VERSION ""

NS_ :

BS_:

BU_: CH DIPF DIPR ETH FC HVI HVS PARTY SDCV VEH VIRT

BO_ 905 DAS_status2: 8 PARTY
 SG_ DAS_status2Checksum : 56|8@1+ (1,0) [0|255] ""  aps
 SG_ DAS_status2Counter : 52|4@1+ (1,0) [0|15] ""  aps
 SG_ DAS_longCollisionWarning : 48|4@1+ (1,0) [0|15] ""  aps
 SG_ DAS_ppOffsetDesiredRamp : 40|8@1+ (0.01,-1.28) [-1.28|1.27] "m"  aps
 SG_ DAS_driverInteractionLevel : 38|2@1+ (1,0) [0|2] ""  aps
 SG_ DAS_robState : 36|2@1+ (1,0) [0|3] ""  aps
 SG_ DAS_radarTelemetry : 34|2@1+ (1,0) [0|2] ""  aps
 SG_ DAS_lssState : 31|3@1+ (1,0) [0|7] ""  aps
 SG_ DAS_ACC_report : 26|5@1+ (1,0) [0|24] ""  aps
 SG_ DAS_pmmCameraFaultReason : 24|2@1+ (1,0) [0|2] ""  aps
 SG_ DAS_pmmSysFaultReason : 21|3@1+ (1,0) [0|7] ""  aps
 SG_ DAS_pmmRadarFaultReason : 19|2@1+ (1,0) [0|2] ""  aps
 SG_ DAS_pmmUltrasonicsFaultReason : 16|3@1+ (1,0) [0|4] ""  aps
 SG_ DAS_activationFailureStatus : 14|2@1+ (1,0) [0|2] ""  aps
 SG_ DAS_pmmLoggingRequest : 13|1@1+ (1,0) [0|1] ""  aps
 SG_ DAS_pmmObstacleSeverity : 10|3@1+ (1,0) [0|7] ""  aps
 SG_ DAS_accSpeedLimit : 0|10@1+ (0.4,0) [0|204.6] "mph"  aps

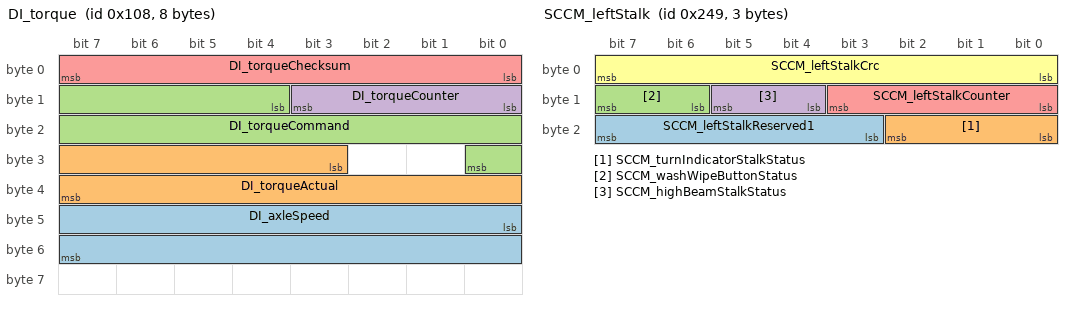
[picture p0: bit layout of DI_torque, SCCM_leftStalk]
BO_ 264 DI_torque: 8 PARTY
 SG_ DI_axleSpeed : 40|16@1- (0.1,0.0) [-2750|2750] "RPM"  epas3s
 SG_ DI_torqueActual : 27|13@1- (2,0) [-7500|7500] "Nm"  X
 SG_ DI_torqueCommand : 12|13@1- (2,0) [-7500|7500] "Nm"  X
 SG_ DI_torqueCounter : 8|4@1+ (1,0) [0|15] ""  epas3s
 SG_ DI_torqueChecksum : 0|8@1+ (1,0) [0|255] ""  epas3s

BO_ 585 SCCM_leftStalk: 3 PARTY
 SG_ SCCM_leftStalkReserved1 : 19|5@1+ (1,0) [0|31] ""  X
 SG_ SCCM_turnIndicatorStalkStatus : 16|3@1+ (1,0) [0|5] ""  park
 SG_ SCCM_washWipeButtonStatus : 14|2@1+ (1,0) [0|3] ""  X
 SG_ SCCM_highBeamStalkStatus : 12|2@1+ (1,0) [0|3] ""  X
 SG_ SCCM_leftStalkCounter : 8|4@1+ (1,0) [0|15] ""  X
 SG_ SCCM_leftStalkCrc : 0|8@1+ (1,0) [0|255] ""  X

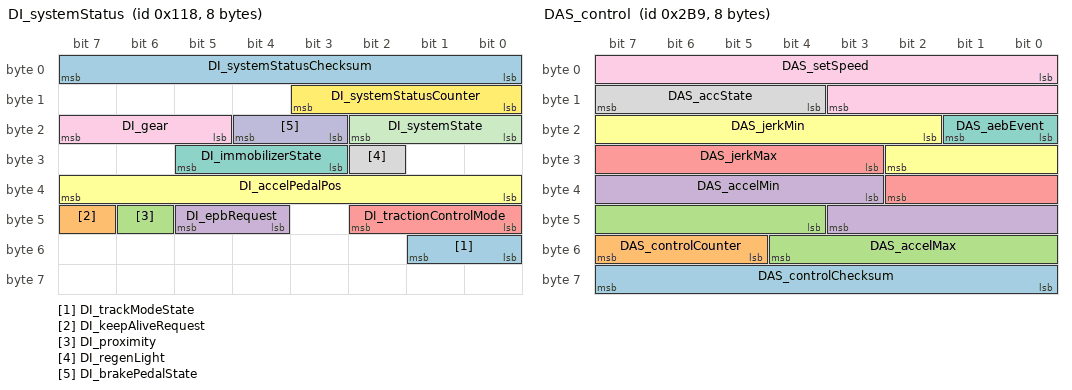
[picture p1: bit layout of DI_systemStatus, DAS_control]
BO_ 280 DI_systemStatus: 8 PARTY
 SG_ DI_trackModeState : 48|2@1+ (1,0) [0|2] ""  X
 SG_ DI_keepAliveRequest : 47|1@1+ (1,0) [0|1] ""  X
 SG_ DI_proximity : 46|1@1+ (1,0) [0|1] ""  X
 SG_ DI_epbRequest : 44|2@1+ (1,0) [0|2] ""  X
 SG_ DI_tractionControlMode : 40|3@1+ (1,0) [0|5] ""  X
 SG_ DI_accelPedalPos : 32|8@1+ (0.4,0) [0|100] "%"  X
 SG_ DI_immobilizerState : 27|3@1+ (1,0) [0|6] ""  X
 SG_ DI_regenLight : 26|1@1+ (1,0) [0|1] ""  X
 SG_ DI_gear : 21|3@1+ (1,0) [0|7] ""  park
 SG_ DI_brakePedalState : 19|2@1+ (1,0) [0|2] ""  X
 SG_ DI_systemState : 16|3@1+ (1,0) [0|5] ""  X
 SG_ DI_systemStatusCounter : 8|4@1+ (1,0) [0|15] ""  X
 SG_ DI_systemStatusChecksum : 0|8@1+ (1,0) [0|255] ""  X

BO_ 697 DAS_control: 8 PARTY
 SG_ DAS_controlChecksum : 56|8@1+ (1,0) [0|255] ""  aps
 SG_ DAS_controlCounter : 53|3@1+ (1,0) [0|7] ""  aps
 SG_ DAS_accelMax : 44|9@1+ (0.04,-15) [-15|5.44] "m/s^2"  aps
 SG_ DAS_accelMin : 35|9@1+ (0.04,-15) [-15|5.44] "m/s^2"  aps
 SG_ DAS_jerkMax : 27|8@1+ (0.034,0) [0|8.67] "m/s^3"  aps
 SG_ DAS_jerkMin : 18|9@1+ (0.018,-9.1) [-9.1|0.097999999999999] "m/s^3"  aps
 SG_ DAS_aebEvent : 16|2@1+ (1,0) [0|3] ""  aps
 SG_ DAS_accState : 12|4@1+ (1,0) [0|15] ""  aps
 SG_ DAS_setSpeed : 0|12@1+ (0.1,0) [0|409.4] "kph"  aps

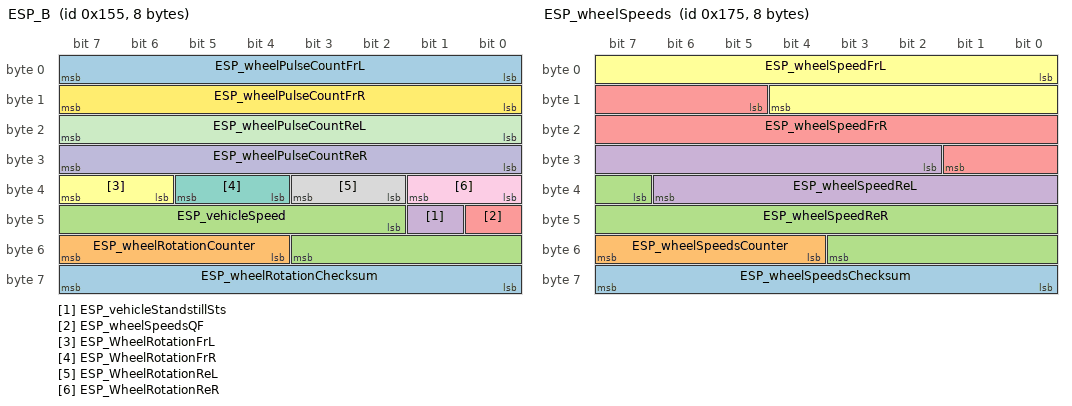
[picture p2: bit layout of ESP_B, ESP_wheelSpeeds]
BO_ 341 ESP_B: 8 PARTY
 SG_ ESP_wheelRotationChecksum : 56|8@1+ (1,0) [0|255] ""  app
 SG_ ESP_wheelRotationCounter : 52|4@1+ (1,0) [0|15] ""  app
 SG_ ESP_vehicleSpeed : 42|10@1+ (0.5,0) [0|511] "kph"  app
 SG_ ESP_vehicleStandstillSts : 41|1@1+ (1,0) [0|1] ""  park
 SG_ ESP_wheelSpeedsQF : 40|1@1+ (1,0) [0|1] ""  epas3s
 SG_ ESP_WheelRotationFrL : 38|2@1+ (1,0) [0|3] ""  aps
 SG_ ESP_WheelRotationFrR : 36|2@1+ (1,0) [0|3] ""  aps
 SG_ ESP_WheelRotationReL : 34|2@1+ (1,0) [0|3] ""  aps
 SG_ ESP_WheelRotationReR : 32|2@1+ (1,0) [0|3] ""  aps
 SG_ ESP_wheelPulseCountReR : 24|8@1+ (1,0) [0|254] "1"  das
 SG_ ESP_wheelPulseCountReL : 16|8@1+ (1,0) [0|254] "1"  das
 SG_ ESP_wheelPulseCountFrR : 8|8@1+ (1,0) [0|254] "1"  app
 SG_ ESP_wheelPulseCountFrL : 0|8@1+ (1,0) [0|254] "1"  app

BO_ 373 ESP_wheelSpeeds: 8 CH
 SG_ ESP_wheelSpeedsChecksum : 56|8@1+ (1,0) [0|255] ""  das
 SG_ ESP_wheelSpeedsCounter : 52|4@1+ (1,0) [0|15] ""  das
 SG_ ESP_wheelSpeedReR : 39|13@1+ (0.04,0) [0|327.64] "km/h"  das
 SG_ ESP_wheelSpeedReL : 26|13@1+ (0.04,0) [0|327.64] "km/h"  das
 SG_ ESP_wheelSpeedFrR : 13|13@1+ (0.04,0) [0|327.64] "km/h"  das
 SG_ ESP_wheelSpeedFrL : 0|13@1+ (0.04,0) [0|327.64] "km/h"  das

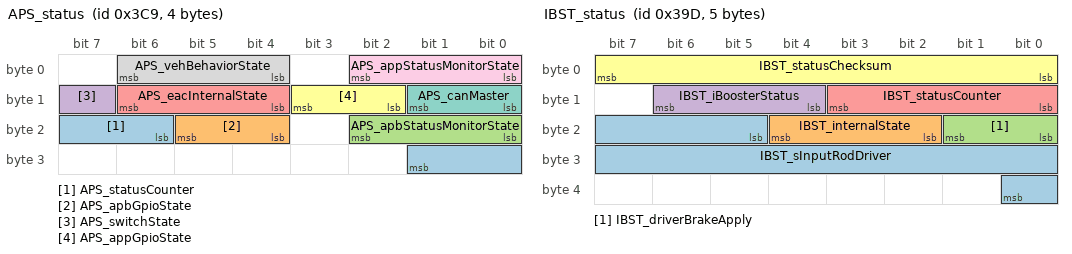
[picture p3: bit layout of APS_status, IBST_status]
BO_ 969 APS_status: 4 PARTY
 SG_ APS_statusCounter : 22|4@1+ (1,0) [0|15] ""  X
 SG_ APS_apbGpioState : 20|2@1+ (1,0) [0|3] ""  gtw
 SG_ APS_apbStatusMonitorState : 16|3@1+ (1,0) [0|7] ""  gtw
 SG_ APS_switchState : 15|1@1+ (1,0) [0|1] ""  X
 SG_ APS_eacInternalState : 12|3@1+ (1,0) [0|7] ""  gtw
 SG_ APS_appGpioState : 10|2@1+ (1,0) [0|3] ""  gtw
 SG_ APS_canMaster : 8|2@1+ (1,0) [0|3] ""  gtw
 SG_ APS_vehBehaviorState : 4|3@1+ (1,0) [0|7] ""  gtw
 SG_ APS_appStatusMonitorState : 0|3@1+ (1,0) [0|7] ""  gtw

BO_ 925 IBST_status: 5 PARTY
 SG_ IBST_sInputRodDriver : 21|12@1+ (0.015625,-5) [-5|47] "mm"  gtw
 SG_ IBST_internalState : 18|3@1+ (1,0) [0|6] ""  gtw
 SG_ IBST_driverBrakeApply : 16|2@1+ (1,0) [0|3] ""  gtw
 SG_ IBST_iBoosterStatus : 12|3@1+ (1,0) [0|6] ""  gtw
 SG_ IBST_statusCounter : 8|4@1+ (1,0) [0|15] ""  X
 SG_ IBST_statusChecksum : 0|8@1+ (1,0) [0|255] ""  X

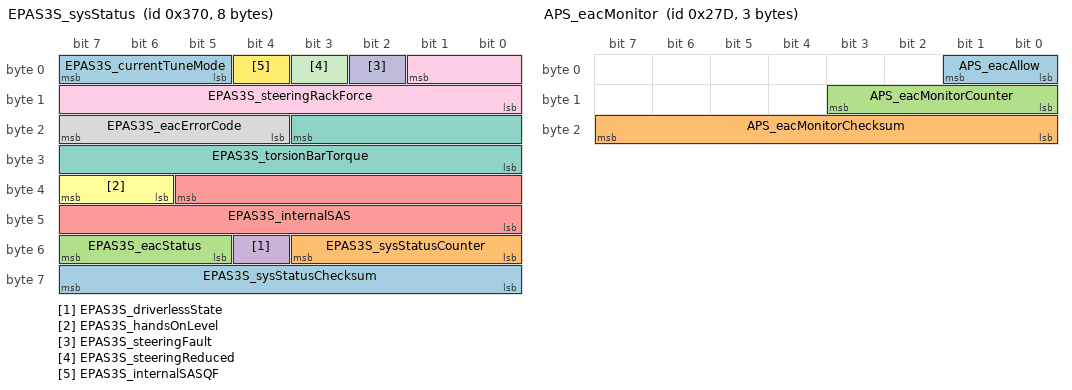
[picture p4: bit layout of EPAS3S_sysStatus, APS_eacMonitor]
BO_ 880 EPAS3S_sysStatus: 8 PARTY
 SG_ EPAS3S_sysStatusChecksum : 56|8@1+ (1,0) [0|255] ""  park
 SG_ EPAS3S_sysStatusCounter : 48|4@1+ (1,0) [0|15] ""  gtw
 SG_ EPAS3S_eacStatus : 55|3@0+ (1,0) [0|7] ""  das
 SG_ EPAS3S_driverlessState : 52|1@0+ (1,0) [0|1] ""  das
 SG_ EPAS3S_internalSAS : 37|14@0+ (0.1,-819.2) [-819.2|819] "deg"  das
 SG_ EPAS3S_handsOnLevel : 39|2@0+ (1,0) [0|3] ""  das
 SG_ EPAS3S_torsionBarTorque : 19|12@0+ (0.01,-20.5) [-20.5|20.45] "Nm"  das
 SG_ EPAS3S_eacErrorCode : 23|4@0+ (1,0) [0|15] ""  das
 SG_ EPAS3S_steeringRackForce : 1|10@0+ (50,-25575) [-25575|25575] "N"  gtw
 SG_ EPAS3S_steeringFault : 2|1@0+ (1,0) [0|1] ""  das
 SG_ EPAS3S_steeringReduced : 3|1@0+ (1,0) [0|1] ""  das
 SG_ EPAS3S_internalSASQF : 4|1@0+ (1,0) [0|1] ""  gtw
 SG_ EPAS3S_currentTuneMode : 7|3@0+ (1,0) [0|5] ""  gtw

BO_ 637 APS_eacMonitor: 3 PARTY
 SG_ APS_eacAllow : 0|2@1+ (1,0) [0|0] "" X
 SG_ APS_eacMonitorChecksum : 16|8@1+ (1,0) [0|0] "" X
 SG_ APS_eacMonitorCounter : 8|4@1+ (1,0) [0|0] "" X

BO_ 545 VCFRONT_LVPowerState: 8 CH
 SG_ VCFRONT_LVPowerStateChecksum : 56|8@1+ (1,0) [0|255] ""  ibst
 SG_ VCFRONT_LVPowerStateCounter : 52|4@1+ (1,0) [0|15] ""  ibst
 SG_ VCFRONT_uiAudioLVState m0 : 50|2@1+ (1,0) [0|3] ""  X
 SG_ VCFRONT_uiHiCurrentLVState m0 : 48|2@1+ (1,0) [0|3] ""  X
 SG_ VCFRONT_vcrightHiCurrentLVState m0 : 46|2@1+ (1,0) [0|3] ""  X
 SG_ VCFRONT_vcleftHiCurrentLVState m0 : 44|2@1+ (1,0) [0|3] ""  X
 SG_ VCFRONT_ocsLVRequest m0 : 42|2@1+ (1,0) [0|3] ""  X
 SG_ VCFRONT_oilPumpRearLVRequest m0 : 40|2@1+ (1,0) [0|3] ""  X
 SG_ VCFRONT_oilPumpFrontLVState m0 : 38|2@1+ (1,0) [0|3] ""  X
 SG_ VCFRONT_disLVState m0 : 36|2@1+ (1,0) [0|3] ""  X
 SG_ VCFRONT_diLVRequest m0 : 34|2@1+ (1,0) [0|3] ""  X
 SG_ VCFRONT_das2HighCurrentLVState m0 : 32|2@1+ (1,0) [0|3] ""  das
 SG_ VCFRONT_das1HighCurrentLVState m0 : 30|2@1+ (1,0) [0|3] ""  das
 SG_ VCFRONT_amplifierLVRequest m0 : 28|2@1+ (1,0) [0|3] ""  X
 SG_ VCFRONT_tunerLVRequest m0 : 26|2@1+ (1,0) [0|3] ""  X
 SG_ VCFRONT_iBoosterLVState m0 : 24|2@1+ (1,0) [0|3] ""  ibst
 SG_ VCFRONT_rcmLVRequest m0 : 22|2@1+ (1,0) [0|3] ""  rcm
 SG_ VCFRONT_tpmsLVRequest m0 : 20|2@1+ (1,0) [0|3] ""  tpms
 SG_ VCFRONT_sccmLVRequest m0 : 18|2@1+ (1,0) [0|3] ""  X
 SG_ VCFRONT_pcsLVState m1 : 16|2@1+ (1,0) [0|3] ""  X
 SG_ VCFRONT_ptcLVRequest m0 : 16|2@1+ (1,0) [0|3] ""  X
 SG_ VCFRONT_hvacCompLVState m0 : 14|2@1+ (1,0) [0|3] ""  X
 SG_ VCFRONT_tasLVState m1 : 14|2@1+ (1,0) [0|3] ""  X
 SG_ VCFRONT_hvcLVRequest m1 : 12|2@1+ (1,0) [0|3] ""  X
 SG_ VCFRONT_radcLVState m0 : 12|2@1+ (1,0) [0|3] ""  X
 SG_ VCFRONT_epasLVState m1 : 10|2@1+ (1,0) [0|3] ""  epas3s
 SG_ VCFRONT_espLVState m0 : 10|2@1+ (1,0) [0|3] ""  ibst
 SG_ VCFRONT_parkLVState m0 : 8|2@1+ (1,0) [0|3] ""  X
 SG_ VCFRONT_cpLVRequest m1 : 8|2@1+ (1,0) [0|3] ""  X
 SG_ VCFRONT_vehiclePowerState : 5|2@1+ (1,0) [0|3] ""  park
 SG_ VCFRONT_LVPowerStateIndex M : 0|5@1+ (1,0) [0|1] ""  epas3s

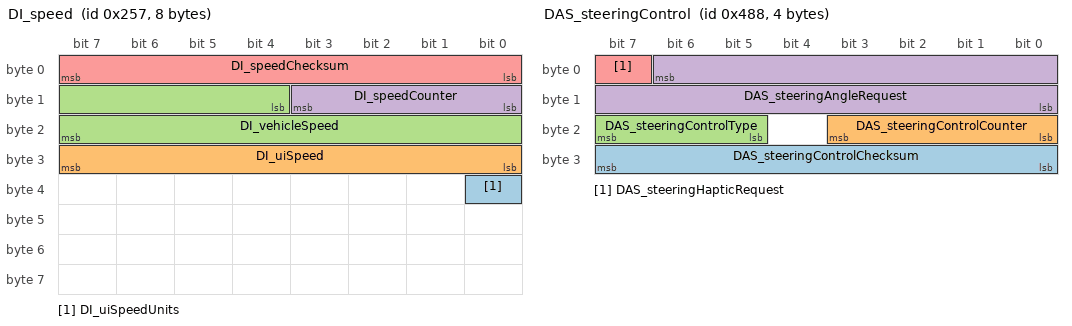
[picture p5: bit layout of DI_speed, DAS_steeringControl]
BO_ 599 DI_speed: 8 PARTY
 SG_ DI_uiSpeedUnits : 32|1@1+ (1,0) [0|1] ""  das
 SG_ DI_uiSpeed : 24|8@1+ (1,0) [0|254] ""  das
 SG_ DI_vehicleSpeed : 12|12@1+ (0.08,-40) [-40|285] "kph"  park
 SG_ DI_speedCounter : 8|4@1+ (1,0) [0|15] ""  park
 SG_ DI_speedChecksum : 0|8@1+ (1,0) [0|255] ""  park

BO_ 605 DAS_road: 6 XXX
 SG_ DAS_stopLineDist : 16|8@1+ (0.5,0) [0|127.5] "m" XXX
 SG_ DAS_trafficLightColor : 26|3@0+ (1,0) [0|7] "" XXX

BO_ 1160 DAS_steeringControl: 4 PARTY
 SG_ DAS_steeringControlChecksum : 24|8@1+ (1,0) [0|255] ""  aps
 SG_ DAS_steeringControlCounter : 16|4@1+ (1,0) [0|15] ""  aps
 SG_ DAS_steeringControlType : 23|3@0+ (1,0) [0|7] ""  aps
 SG_ DAS_steeringAngleRequest : 6|15@0+ (0.1,-1638.35) [-1638.35|1638.35] "deg"  aps
 SG_ DAS_steeringHapticRequest : 7|1@0+ (1,0) [0|1] ""  aps

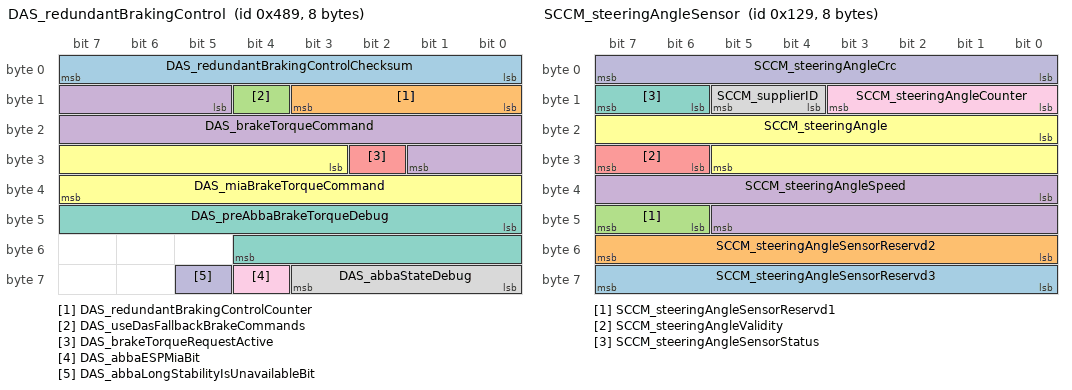
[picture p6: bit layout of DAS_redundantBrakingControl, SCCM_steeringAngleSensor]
BO_ 1161 DAS_redundantBrakingControl: 8 XXX
 SG_ DAS_redundantBrakingControlChecksum : 0|8@1+ (1,0) [0|255] "" XXX
 SG_ DAS_redundantBrakingControlCounter : 8|4@1+ (1,0) [0|15] "" XXX
 SG_ DAS_useDasFallbackBrakeCommands : 12|1@1+ (1,0) [0|1] "" XXX
 SG_ DAS_brakeTorqueCommand : 13|13@1+ (3,0) [0|24573] "" XXX
 SG_ DAS_brakeTorqueRequestActive : 26|1@1+ (1,0) [0|1] "" XXX
 SG_ DAS_miaBrakeTorqueCommand : 27|13@1+ (3,0) [0|24573] "" XXX
 SG_ DAS_preAbbaBrakeTorqueDebug : 40|13@1+ (3,0) [0|24573] "" XXX
 SG_ DAS_abbaStateDebug : 56|4@1+ (1,0) [0|15] "" XXX
 SG_ DAS_abbaESPMiaBit : 60|1@1+ (1,0) [0|1] "" XXX
 SG_ DAS_abbaLongStabilityIsUnavailableBit : 61|1@1+ (1,0) [0|1] "" XXX

BO_ 297 SCCM_steeringAngleSensor: 8 PARTY
 SG_ SCCM_steeringAngleSensorReservd3 : 56|8@1+ (1,0) [0|255] ""  X
 SG_ SCCM_steeringAngleSensorReservd2 : 48|8@1+ (1,0) [0|255] ""  X
 SG_ SCCM_steeringAngleSensorReservd1 : 46|2@1+ (1,0) [0|3] ""  X
 SG_ SCCM_steeringAngleSpeed : 32|14@1+ (0.5,-4096) [-4096|4095.5] "deg/s"  park
 SG_ SCCM_steeringAngleValidity : 30|2@1+ (1,0) [0|3] ""  park
 SG_ SCCM_steeringAngle : 16|14@1+ (0.1,-819.2) [-819.2|819] "deg"  epas3s
 SG_ SCCM_steeringAngleSensorStatus : 14|2@1+ (1,0) [0|3] ""  epas3s
 SG_ SCCM_supplierID : 12|2@1+ (1,0) [0|3] ""  park
 SG_ SCCM_steeringAngleCounter : 8|4@1+ (1,0) [0|15] ""  epas3s
 SG_ SCCM_steeringAngleCrc : 0|8@1+ (1,0) [0|255] ""  epas3s

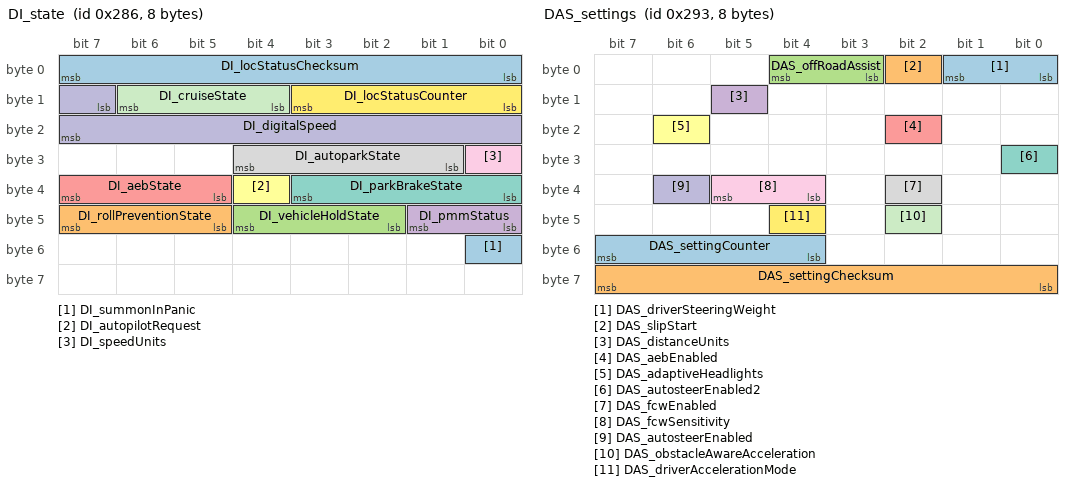
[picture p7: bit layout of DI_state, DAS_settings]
BO_ 646 DI_state: 8 ETH
 SG_ DI_summonInPanic : 48|1@1+ (1,0) [0|0] ""  X
 SG_ DI_rollPreventionState : 45|3@1+ (1,0) [0|0] ""  X
 SG_ DI_vehicleHoldState : 42|3@1+ (1,0) [0|0] ""  X
 SG_ DI_pmmStatus : 40|2@1+ (1,0) [0|0] ""  X
 SG_ DI_aebState : 37|3@1+ (1,0) [0|0] ""  X
 SG_ DI_autopilotRequest : 36|1@1+ (1,0) [0|0] ""  X
 SG_ DI_parkBrakeState : 32|4@1+ (1,0) [0|0] ""  X
 SG_ DI_autoparkState : 25|4@1+ (1,0) [0|0] ""  X
 SG_ DI_speedUnits : 24|1@1+ (1,0) [0|0] ""  X
 SG_ DI_digitalSpeed : 15|9@1+ (0.5,0) [0|0] "speed"  X
 SG_ DI_cruiseState : 12|3@1+ (1,0) [0|0] ""  X
 SG_ DI_locStatusCounter : 8|4@1+ (1,0) [0|0] ""  X
 SG_ DI_locStatusChecksum : 0|8@1+ (1,0) [0|0] ""  X

BO_ 659 DAS_settings: 8 XXX
 SG_ DAS_driverSteeringWeight : 1|2@0+ (1,0) [0|255] "" XXX
 SG_ DAS_slipStart : 2|1@0+ (1,0) [0|1] "" XXX
 SG_ DAS_offRoadAssist : 3|2@1+ (1,0) [0|63] "" XXX
 SG_ DAS_distanceUnits : 13|1@1+ (1,0) [0|255] "" XXX
 SG_ DAS_aebEnabled : 18|1@0+ (1,0) [0|255] "" XXX
 SG_ DAS_adaptiveHeadlights : 22|1@1+ (1,0) [0|31] "" XXX
 SG_ DAS_autosteerEnabled2 : 24|1@0+ (1,0) [0|1] "" XXX
 SG_ DAS_fcwEnabled : 34|1@0+ (1,0) [0|1] "" XXX
 SG_ DAS_fcwSensitivity : 37|2@0+ (1,0) [0|63] "" XXX
 SG_ DAS_autosteerEnabled : 38|1@0+ (1,0) [0|1] "" XXX
 SG_ DAS_obstacleAwareAcceleration : 42|1@0+ (1,0) [0|1] "" XXX
 SG_ DAS_driverAccelerationMode : 44|1@1+ (1,0) [0|127] "" XXX
 SG_ DAS_settingCounter : 52|4@1+ (1,0) [0|15] "" XXX
 SG_ DAS_settingChecksum : 56|8@1+ (1,0) [0|255] "" XXX

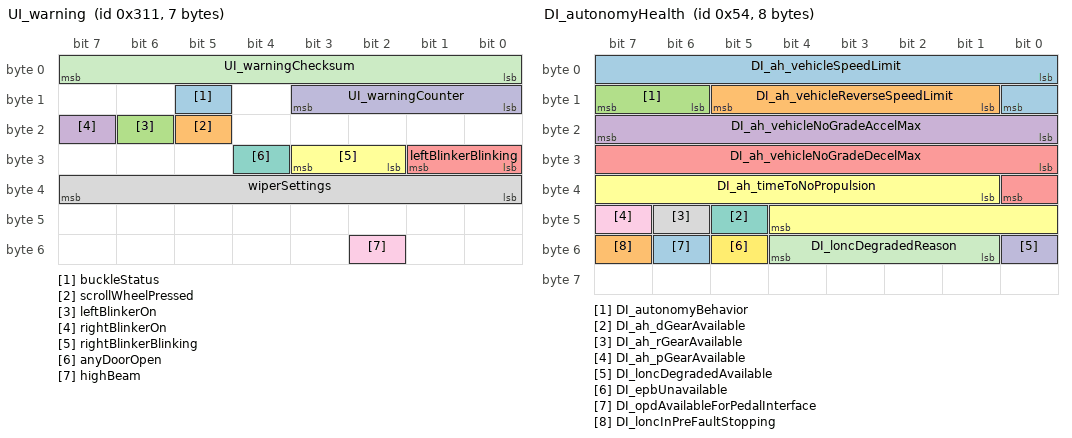
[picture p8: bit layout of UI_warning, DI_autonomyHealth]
BO_ 785 UI_warning: 7 XXX
 SG_ buckleStatus : 13|1@0+ (1,0) [0|1] "" XXX
 SG_ scrollWheelPressed : 21|1@0+ (1,0) [0|1] "" XXX
 SG_ leftBlinkerOn : 22|1@0+ (1,0) [0|1] "" XXX
 SG_ rightBlinkerOn : 23|1@0+ (1,0) [0|1] "" XXX
 SG_ leftBlinkerBlinking : 25|2@0+ (1,0) [0|3] "" XXX
 SG_ rightBlinkerBlinking : 26|2@1+ (1,0) [0|15] "" XXX
 SG_ anyDoorOpen : 28|1@0+ (1,0) [0|1] "" XXX
 SG_ wiperSettings : 39|8@0+ (1,0) [0|255] "" XXX
 SG_ highBeam : 50|1@0+ (1,0) [0|1] "" XXX
 SG_ UI_warningCounter : 8|4@1+ (1,0) [0|15] "" XXX
 SG_ UI_warningChecksum : 0|8@1+ (1,0) [0|255] "" XXX

BO_ 923 DAS_status: 8 PARTY
 SG_ DAS_statusChecksum : 56|8@1+ (1,0) [0|255] ""  aps
 SG_ DAS_statusCounter : 52|4@1+ (1,0) [0|15] ""  aps
 SG_ DAS_summonAvailable : 51|1@1+ (1,0) [0|1] ""  aps
 SG_ DAS_autoLaneChangeState : 46|5@1+ (1,0) [0|31] ""  aps
 SG_ DAS_autopilotHandsOnState : 42|4@1+ (1,0) [0|15] ""  aps
 SG_ DAS_fleetSpeedState : 40|2@1+ (1,0) [0|3] ""  aps
 SG_ DAS_laneDepartureWarning : 37|3@1+ (1,0) [0|5] ""  aps
 SG_ DAS_csaState : 35|2@1+ (1,0) [0|3] ""  aps
 SG_ DAS_sideCollisionInhibit : 34|1@1+ (1,0) [0|1] ""  aps
 SG_ DAS_sideCollisionWarning : 32|2@1+ (1,0) [0|3] ""  aps
 SG_ DAS_sideCollisionAvoid : 30|2@1+ (1,0) [0|3] ""  aps
 SG_ DAS_summonRvsLeashReached : 29|1@1+ (1,0) [0|1] ""  aps
 SG_ DAS_summonFwdLeashReached : 28|1@1+ (1,0) [0|1] ""  aps
 SG_ DAS_autoparkWaitingForBrake : 26|1@1+ (1,0) [0|1] ""  gtw
 SG_ DAS_autoParked : 25|1@1+ (1,0) [0|1] ""  aps
 SG_ DAS_autoparkReady : 24|1@1+ (1,0) [0|1] ""  aps
 SG_ DAS_forwardCollisionWarning : 22|2@1+ (1,0) [0|3] ""  aps
 SG_ DAS_heaterState : 21|1@1+ (1,0) [0|1] ""  gtw
 SG_ DAS_visionOnlySpeedLimit : 16|5@1+ (5,0) [0|150] "kph/mph"  aps
 SG_ DAS_summonClearedGate : 15|1@1+ (1,0) [0|1] ""  aps
 SG_ DAS_summonObstacle : 14|1@1+ (1,0) [0|1] ""  aps
 SG_ DAS_suppressSpeedWarning : 13|1@1+ (1,0) [0|1] ""  aps
 SG_ DAS_fusedSpeedLimit : 8|5@1+ (5,0) [0|150] "kph/mph"  aps
 SG_ DAS_blindSpotRearRight : 6|2@1+ (1,0) [0|3] ""  aps
 SG_ DAS_blindSpotRearLeft : 4|2@1+ (1,0) [0|3] ""  aps
 SG_ DAS_autopilotState : 0|4@1+ (1,0) [0|15] ""  aps

BO_ 325 ESP_status: 8 PARTY
 SG_ ESP_absBrakeEvent2 : 22|2@1+ (1,0) [0|0] ""  X
 SG_ ESP_absFaultLamp : 17|1@1+ (1,0) [0|0] ""  X
 SG_ ESP_brakeApply : 31|1@1+ (1,0) [0|0] ""  X
 SG_ ESP_brakeDiscWipingActive : 28|1@1+ (1,0) [0|0] ""  X
 SG_ ESP_brakeLamp : 21|1@1+ (1,0) [0|0] ""  X
 SG_ ESP_brakeTorqueTarget : 51|13@1+ (2,0) [0|0] "Nm"  X
 SG_ ESP_btcTargetState : 38|2@1+ (1,0) [0|0] ""  X
 SG_ ESP_cdpStatus : 34|2@1+ (1,0) [0|0] ""  X
 SG_ ESP_driverBrakeApply : 29|2@1+ (1,0) [0|0] ""  X
 SG_ ESP_ebdFaultLamp : 16|1@1+ (1,0) [0|0] ""  X
 SG_ ESP_ebrStandstillSkid : 48|1@1+ (1,0) [0|0] ""  X
 SG_ ESP_ebrStatus : 49|2@1+ (1,0) [0|0] ""  X
 SG_ ESP_espFaultLamp : 18|1@1+ (1,0) [0|0] ""  X
 SG_ ESP_espLampFlash : 20|1@1+ (1,0) [0|0] ""  X
 SG_ ESP_espModeActive : 12|2@1+ (1,0) [0|0] ""  X
 SG_ ESP_hydraulicBoostEnabled : 19|1@1+ (1,0) [0|0] ""  X
 SG_ ESP_lateralAccelQF : 25|1@1+ (1,0) [0|0] ""  X
 SG_ ESP_longitudinalAccelQF : 24|1@1+ (1,0) [0|0] ""  X
 SG_ ESP_ptcTargetState : 36|2@1+ (1,0) [0|0] ""  X
 SG_ ESP_stabilityControlSts2 : 14|2@1+ (1,0) [0|0] ""  X
 SG_ ESP_statusChecksum : 0|8@1+ (1,0) [0|0] ""  X
 SG_ ESP_statusCounter : 8|4@1+ (1,0) [0|0] ""  X
 SG_ ESP_steeringAngleQF : 27|1@1+ (1,0) [0|0] ""  X
 SG_ ESP_yawRateQF : 26|1@1+ (1,0) [0|0] ""  X

BO_ 84 DI_autonomyHealth: 8 XXX
 SG_ DI_ah_vehicleSpeedLimit : 0|9@1+ (1,0) [0|511] "" XXX
 SG_ DI_ah_vehicleReverseSpeedLimit : 9|5@1+ (1,0) [0|31] "" XXX
 SG_ DI_autonomyBehavior : 14|2@1+ (1,0) [0|3] "" XXX
 SG_ DI_ah_vehicleNoGradeAccelMax : 16|8@1+ (0.04,0) [0|10.2] "" XXX
 SG_ DI_ah_vehicleNoGradeDecelMax : 24|9@1+ (0.04,0) [0|20.44] "" XXX
 SG_ DI_ah_timeToNoPropulsion : 33|12@1+ (1,0) [0|4095] "" XXX
 SG_ DI_ah_dGearAvailable : 45|1@1+ (1,0) [0|1] "" XXX
 SG_ DI_ah_rGearAvailable : 46|1@1+ (1,0) [0|1] "" XXX
 SG_ DI_ah_pGearAvailable : 47|1@1+ (1,0) [0|1] "" XXX
 SG_ DI_loncDegradedAvailable : 48|1@1+ (1,0) [0|1] "" XXX
 SG_ DI_loncDegradedReason : 49|4@1+ (1,0) [0|15] "" XXX
 SG_ DI_epbUnavailable : 53|1@1+ (1,0) [0|1] "" XXX
 SG_ DI_opdAvailableForPedalInterface : 54|1@1+ (1,0) [0|1] "" XXX
 SG_ DI_loncInPreFaultStopping : 55|1@1+ (1,0) [0|1] "" XXX

BO_ 521 DAS_longControl: 8 XXX
 SG_ DAS_longControlChecksum : 0|8@1+ (1,0) [0|255] "" XXX
 SG_ DAS_longControlCounter : 8|3@1+ (1,0) [0|7] "" XXX
 SG_ DAS_gearRequest : 11|2@1+ (1,0) [0|3] "" XXX
 SG_ DAS_velocityProfile_accelFwd_t0 m3 : 13|11@1- (0.012,-0.216) [-12.504|12.06] "" XXX
 SG_ DAS_torqueProfiler_accelMinPed m2 : 14|9@1+ (0.04,-15) [-15|5.44] "" XXX
 SG_ DAS_aebControl_active m4 : 16|2@1+ (1,0) [0|3] "" XXX
 SG_ DAS_pedalControl_accelPedalPos m5 : 16|12@1+ (0.025,0) [0|102.375] "" XXX
 SG_ DAS_torqueControl_sysTorqueCommandFwd m6 : 16|15@1- (2,0) [-32768|32766] "" XXX
 SG_ DAS_aebControl_targetAccelDis m4 : 18|11@1- (0.01,-7.5) [-17.74|2.73] "" XXX
 SG_ DAS_torqueProfiler_accelMaxPed m2 : 23|9@1+ (0.04,-15) [-15|5.44] "" XXX
 SG_ DAS_velocityProfile_jerkFwd_t0t1 m3 : 24|8@1- (0.12,0) [-15.36|15.24] "" XXX
 SG_ DAS_pedalControl_brakeTorqueCommand m5 : 32|13@1+ (3.5,0) [0|28668.5] "" XXX
 SG_ DAS_torqueControl_standstillRequest m6 : 32|1@1+ (1,0) [0|1] "" XXX
 SG_ DAS_torqueProfiler_targetSpeedPed m2 : 32|12@1+ (0.1,0) [0|409.5] "" XXX
 SG_ DAS_velocityProfile_futureTargetSpeedFwd m3 : 32|12@1- (0.08,80.08) [-83.76|243.84] "" XXX
 SG_ DAS_torqueProfiler_jerkMinPed m2 : 44|9@1+ (0.03,-15.232) [-15.232|0.098] "" XXX
 SG_ DAS_velocityProfile_jerkFwd_t1t2 m3 : 44|8@1- (0.12,0) [-15.36|15.24] "" XXX
 SG_ DAS_pedalControl_noGradeAccelMax m5 : 45|6@1+ (0.25,0) [0|15.75] "" XXX
 SG_ DAS_pedalControl_speedMax m5 : 51|8@1+ (1,0) [0|255] "" XXX
 SG_ DAS_velocityProfile_maxAllowedTargetErrorReg m3 : 52|6@1- (0.1,1.1) [-2.1|4.2] "" XXX
 SG_ DAS_torqueProfiler_jerkMaxPed m2 : 53|8@1+ (0.059,0) [0|15.045] "" XXX
 SG_ DAS_velocityProfile_calcDelay m3 : 58|3@1+ (0.006666666666666667,0) [0|0.046667] "" XXX
 SG_ DAS_longControlStack M : 61|3@1+ (1,0) [0|7] "" XXX

BO_ 2047 GTW_carConfig: 8 XXX
 SG_ GTW_carConfigMultiplexer M : 0|8@1+ (1,0) [0|255] "" XXX
 SG_ GTW_birthday m4 : 8|32@1+ (1,0) [0|4294967295] "" XXX
 SG_ GTW_deliveryStatus m1 : 8|1@1+ (1,0) [0|1] "" XXX
 SG_ GTW_exteriorTrimType m2 : 8|1@1+ (1,0) [0|1] "" XXX
 SG_ GTW_gloveboxUSBType m5 : 8|2@1+ (1,0) [0|3] "" XXX
 SG_ GTW_mapRegion m3 : 8|4@1+ (1,0) [0|15] "" XXX
 SG_ GTW_rcmUndersideAbuseZThreshold m9 : 8|3@1+ (1,0) [0|7] "" XXX
 SG_ GTW_fasciaType m7 : 9|4@1+ (1,0) [0|15] "" XXX
 SG_ GTW_frontSeatHeaters m2 : 9|1@1+ (1,0) [0|1] "" XXX
 SG_ GTW_wiperMotorType m6 : 9|1@1+ (1,0) [0|1] "" XXX
 SG_ GTW_cabinPTCHeaterType m1 : 10|1@1+ (1,0) [0|1] "" XXX
 SG_ GTW_coolantPumpType m5 : 10|3@1+ (1,0) [0|7] "" XXX
 SG_ GTW_frontOverheadConsoleType m6 : 10|2@1+ (1,0) [0|3] "" XXX
 SG_ GTW_rearSeatHeaters m2 : 10|1@1+ (1,0) [0|1] "" XXX
 SG_ GTW_sohRegulatoryStatus m8 : 10|1@1+ (1,0) [0|1] "" XXX
 SG_ GTW_rcmUndersideAbuseYThreshold m9 : 11|3@1+ (1,0) [0|7] "" XXX
 SG_ GTW_rightHandDrive m1 : 11|1@1+ (1,0) [0|1] "" XXX
 SG_ GTW_eCallAntennaHW m2 : 12|1@1+ (1,0) [0|1] "" XXX
 SG_ GTW_performancePackage m3 : 12|3@1+ (1,0) [0|7] "" XXX
 SG_ GTW_rearLightType m1 : 12|2@1+ (1,0) [0|3] "" XXX
 SG_ GTW_shifterType m6 : 12|1@1+ (1,0) [0|1] "" XXX
 SG_ GTW_compressorType m6 : 13|4@1+ (1,0) [0|15] "" XXX
 SG_ GTW_epblHwType m5 : 13|4@1+ (1,0) [0|15] "" XXX
 SG_ GTW_homelinkType m2 : 13|1@1+ (1,0) [0|1] "" XXX
 SG_ GTW_powerSteeringColumn m7 : 13|1@1+ (1,0) [0|1] "" XXX
 SG_ GTW_frontSeatHeaterType m7 : 14|1@1+ (1,0) [0|1] "" XXX
 SG_ GTW_headlamps m1 : 14|2@1+ (1,0) [0|3] "" XXX
 SG_ GTW_rcmUndersideAbuseWindow m9 : 14|2@1+ (1,0) [0|3] "" XXX
 SG_ GTW_vdcType m2 : 14|1@1+ (1,0) [0|1] "" XXX
 SG_ GTW_softPerformanceLimit m7 : 15|4@1+ (1,0) [0|15] "" XXX
 SG_ GTW_country m1 : 16|16@1+ (1,0) [0|65535] "" XXX
 SG_ GTW_epbrHwType m5 : 17|4@1+ (1,0) [0|15] "" XXX
 SG_ GTW_m3yBusArchitecture m8 : 17|2@1+ (1,0) [0|3] "" XXX
 SG_ GTW_memoryMirrors m2 : 17|1@1+ (1,0) [0|1] "" XXX
 SG_ GTW_twelveVBatteryType m6 : 17|3@1+ (1,0) [0|7] "" XXX
 SG_ GTW_chassisType m3 : 18|4@1+ (1,0) [0|15] "" XXX
 SG_ GTW_powerLiftgateType m2 : 18|2@1+ (1,0) [0|3] "" XXX
 SG_ GTW_efuseSWConfig m6 : 20|3@1+ (1,0) [0|7] "" XXX
 SG_ GTW_lumbarECUType m2 : 20|4@1+ (1,0) [0|15] "" XXX
 SG_ GTW_blowerMotorType m5 : 21|2@1+ (1,0) [0|3] "" XXX
 SG_ GTW_interiorUpperTrimType m8 : 21|1@1+ (1,0) [0|1] "" XXX
 SG_ GTW_airSuspension m3 : 22|2@1+ (1,0) [0|3] "" XXX
 SG_ GTW_alcoholInterlockType m7 : 22|1@1+ (1,0) [0|1] "" XXX
 SG_ GTW_blindSpotIndicatorLightType m8 : 22|2@1+ (1,0) [0|3] "" XXX
 SG_ GTW_immersiveAudio m7 : 23|2@1+ (1,0) [0|3] "" XXX
 SG_ GTW_bleEndpointUpdateMethod m6 : 24|1@1+ (1,0) [0|1] "" XXX
 SG_ GTW_centerConsoleControllerType m3 : 24|2@1+ (1,0) [0|3] "" XXX
 SG_ GTW_powerMirrorFoldType m5 : 24|1@1+ (1,0) [0|1] "" XXX
 SG_ GTW_rearSeatHeaterType m2 : 24|2@1+ (1,0) [0|3] "" XXX
 SG_ GTW_wiperMotorAsicType m8 : 24|2@1+ (1,0) [0|3] "" XXX
 SG_ GTW_steeringWheelControllerType m6 : 25|3@1+ (1,0) [0|7] "" XXX
 SG_ GTW_autopilotCameraType m3 : 26|1@1+ (1,0) [0|1] "" XXX
 SG_ GTW_auxParkLamps m2 : 26|2@1+ (1,0) [0|3] "" XXX
 SG_ GTW_passengerOccupancySensorType m7 : 26|3@1+ (1,0) [0|7] "" XXX
 SG_ GTW_connectivityPackage m3 : 27|1@1+ (1,0) [0|1] "" XXX
 SG_ GTW_frontUsbHubType m5 : 27|3@1+ (1,0) [0|7] "" XXX
 SG_ GTW_interiorCabinRadarType m2 : 28|1@1+ (1,0) [0|1] "" XXX
 SG_ GTW_plcSupportType m3 : 28|2@1+ (1,0) [0|3] "" XXX
 SG_ GTW_gloveboxActuatorType m6 : 29|2@1+ (1,0) [0|3] "" XXX
 SG_ GTW_hvacPanelVaneType m2 : 29|1@1+ (1,0) [0|1] "" XXX
 SG_ GTW_badgingVersion m3 : 30|2@1+ (1,0) [0|3] "" XXX
 SG_ GTW_packPerformanceDeviation m7 : 30|3@1+ (1,0) [0|7] "" XXX
 SG_ GTW_superManifoldType m5 : 30|2@1+ (1,0) [0|3] "" XXX
 SG_ GTW_rduCableType m8 : 31|1@1+ (1,0) [0|1] "" XXX
 SG_ GTW_eBuckConfig m2 : 32|1@1+ (1,0) [0|1] "" XXX
 SG_ GTW_epasType m6 : 32|4@1+ (1,0) [0|15] "" XXX
 SG_ GTW_packEnergy m3 : 32|5@1+ (1,0) [0|31] "" XXX
 SG_ GTW_parkTelltaleBehaviorType m8 : 32|1@1+ (1,0) [0|1] "" XXX
 SG_ GTW_rcmLocation m5 : 32|1@1+ (1,0) [0|1] "" XXX
 SG_ GTW_tireType m1 : 32|6@1+ (1,0) [0|63] "" XXX
 SG_ GTW_autopilotExteriorCameraType m5 : 33|1@1+ (1,0) [0|1] "" XXX
 SG_ GTW_epasSubType m9 : 33|1@1+ (1,0) [0|1] "" XXX
 SG_ GTW_steeringHeaterEnabled m2 : 33|1@1+ (1,0) [0|1] "" XXX
 SG_ GTW_activeHighBeam m2 : 34|1@1+ (1,0) [0|1] "" XXX
 SG_ GTW_airbagCutoffSwitch m2 : 35|1@1+ (1,0) [0|1] "" XXX
 SG_ GTW_frontFogLamps m7 : 35|1@1+ (1,0) [0|1] "" XXX
 SG_ GTW_wiperSupplyChainOrigin m9 : 35|2@1+ (1,0) [0|3] "" XXX
 SG_ GTW_homologationRegionOverride m6 : 36|2@1+ (1,0) [0|3] "" XXX
 SG_ GTW_intrusionSensorType m2 : 36|1@1+ (1,0) [0|1] "" XXX
 SG_ GTW_audioType m7 : 37|3@1+ (1,0) [0|7] "" XXX
 SG_ GTW_frontSeatReclinerHardware m3 : 37|2@1+ (1,0) [0|3] "" XXX
 SG_ GTW_sirenType m5 : 37|1@1+ (1,0) [0|1] "" XXX
 SG_ GTW_spoilerType m2 : 37|1@1+ (1,0) [0|1] "" XXX
 SG_ GTW_hornType m5 : 38|1@1+ (1,0) [0|1] "" XXX
 SG_ GTW_roofGlassType m1 : 38|2@1+ (1,0) [0|3] "" XXX
 SG_ GTW_windowCommandsPermissionType m6 : 38|2@1+ (1,0) [0|3] "" XXX
 SG_ GTW_brakeLineSwitchType m3 : 39|1@1+ (1,0) [0|1] "" XXX
 SG_ GTW_interiorCameraType m8 : 39|2@1+ (1,0) [0|3] "" XXX
 SG_ GTW_rearFogLamps m2 : 39|1@1+ (1,0) [0|1] "" XXX
 SG_ GTW_dasHw m1 : 40|3@1+ (1,0) [0|7] "" XXX
 SG_ GTW_eCallEnabled m4 : 40|2@1+ (1,0) [0|3] "" XXX
 SG_ GTW_espValveType m3 : 40|2@1+ (1,0) [0|3] "" XXX
 SG_ GTW_mRecordVersion m9 : 40|1@1+ (1,0) [0|1] "" XXX
 SG_ GTW_roofType m2 : 40|1@1+ (1,0) [0|1] "" XXX
 SG_ GTW_frontFasciaCameraType m8 : 41|2@1+ (1,0) [0|3] "" XXX
 SG_ GTW_autopilot m2 : 42|3@1+ (1,0) [0|7] "" XXX
 SG_ GTW_headlightStepperStallDetectMode m6 : 42|1@1+ (1,0) [0|1] "" XXX
 SG_ GTW_parkAssistECUType m4 : 42|2@1+ (1,0) [0|3] "" XXX
 SG_ GTW_softRange m3 : 42|3@1+ (1,0) [0|7] "" XXX
 SG_ GTW_steeringColumnMotorType m5 : 42|2@1+ (1,0) [0|3] "" XXX
 SG_ GTW_brakeHWType m1 : 43|5@1+ (1,0) [0|31] "" XXX
 SG_ GTW_rgbInteriorLightingEnabled m6 : 43|2@1+ (1,0) [0|3] "" XXX
 SG_ GTW_passengerAirbagType m4 : 44|2@1+ (1,0) [0|3] "" XXX
 SG_ GTW_interiorCamFanType m8 : 45|3@1+ (1,0) [0|7] "" XXX
 SG_ GTW_refrigerantType m3 : 45|2@1+ (1,0) [0|3] "" XXX
 SG_ GTW_superchargingAccess m2 : 45|2@1+ (1,0) [0|3] "" XXX
 SG_ GTW_windshieldWiperHeaterType m6 : 45|1@1+ (1,0) [0|1] "" XXX
 SG_ GTW_forwardRadarHw m4 : 46|2@1+ (1,0) [0|3] "" XXX
 SG_ GTW_frontControllerArchitectureType m7 : 46|1@1+ (1,0) [0|1] "" XXX
 SG_ GTW_driveInterfaceType m6 : 47|1@1+ (1,0) [0|1] "" XXX
 SG_ GTW_exteriorColor m2 : 48|5@1+ (1,0) [0|31] "" XXX
 SG_ GTW_frontSeatType m4 : 48|4@1+ (1,0) [0|15] "" XXX
 SG_ GTW_refrigACLineType m5 : 48|2@1+ (1,0) [0|3] "" XXX
 SG_ GTW_restraintsHardwareType m1 : 48|8@1+ (1,0) [0|255] "" XXX
 SG_ GTW_wheelType m3 : 48|7@1+ (1,0) [0|127] "" XXX
 SG_ GTW_efficiencyPackage m6 : 49|6@1+ (1,0) [0|63] "" XXX
 SG_ GTW_tpmsType m7 : 49|2@1+ (1,0) [0|3] "" XXX
 SG_ GTW_refrigFilterType m5 : 50|2@1+ (1,0) [0|3] "" XXX
 SG_ GTW_authenticationEndpointLayout m7 : 52|3@1+ (1,0) [0|7] "" XXX
 SG_ GTW_diBurnInType m5 : 52|1@1+ (1,0) [0|1] "" XXX
 SG_ GTW_pedestrianWarningSound m2 : 53|2@1+ (1,0) [0|3] "" XXX
 SG_ GTW_specialBadgingType m5 : 53|2@1+ (1,0) [0|3] "" XXX
 SG_ GTW_wirelessPhoneChargerType m4 : 53|2@1+ (1,0) [0|3] "" XXX
 SG_ GTW_chassisSubType m5 : 55|2@1+ (1,0) [0|3] "" XXX
 SG_ GTW_ethernetTunerType m4 : 55|2@1+ (1,0) [0|3] "" XXX
 SG_ GTW_ptcControlMode m3 : 55|2@1+ (1,0) [0|3] "" XXX
 SG_ GTW_steeringColumnUJointType m2 : 55|1@1+ (1,0) [0|1] "" XXX
 SG_ GTW_visorLightType m6 : 55|1@1+ (1,0) [0|1] "" XXX
 SG_ GTW_bPillarNFCParam m2 : 56|1@1+ (1,0) [0|1] "" XXX
 SG_ GTW_drivetrainType m1 : 56|4@1+ (1,0) [0|15] "" XXX
 SG_ GTW_brakeActuationType m3 : 57|3@1+ (1,0) [0|7] "" XXX
 SG_ GTW_frontSeatVentilationType m5 : 57|1@1+ (1,0) [0|1] "" XXX
 SG_ GTW_interiorLighting m2 : 57|3@1+ (1,0) [0|7] "" XXX
 SG_ GTW_socSleepOverride m7 : 57|2@1+ (1,0) [0|3] "" XXX
 SG_ GTW_gnssAntennaType m6 : 58|2@1+ (1,0) [0|3] "" XXX
 SG_ GTW_towPackage m5 : 58|2@1+ (1,0) [0|3] "" XXX
 SG_ GTW_v2xEnabled m9 : 58|1@1+ (1,0) [0|1] "" XXX
 SG_ GTW_r79BehaviorOverride m7 : 59|1@1+ (1,0) [0|1] "" XXX
 SG_ GTW_headlightLevelerType m2 : 60|2@1+ (1,0) [0|3] "" XXX
 SG_ GTW_interiorTrimType m4 : 60|4@1+ (1,0) [0|15] "" XXX
 SG_ GTW_radarHeaterType m1 : 60|3@1+ (1,0) [0|7] "" XXX
 SG_ GTW_repeaterAeroRibType m8 : 60|3@1+ (1,0) [0|7] "" XXX
 SG_ GTW_steeringHeaterType m7 : 60|3@1+ (1,0) [0|7] "" XXX
 SG_ GTW_restraintControlsType m5 : 61|1@1+ (1,0) [0|1] "" XXX
 SG_ GTW_caliperColorType m5 : 62|2@1+ (1,0) [0|3] "" XXX
 SG_ GTW_frontSeatHeatersEnabled m6 : 62|1@1+ (1,0) [0|1] "" XXX
 SG_ GTW_numberHVILNodes m2 : 62|2@1+ (1,0) [0|3] "" XXX
 SG_ GTW_narrowWipingSupported m7 : 63|1@1+ (1,0) [0|1] "" XXX
 SG_ GTW_windshieldWiperHeaterEnabled m6 : 63|1@1+ (1,0) [0|1] "" XXX

BO_ 1861 DI_chassisControl2: 8 XXX
 SG_ DI_gradeAngle : 0|6@1- (0.01,0) [-0.32|0.31] "" XXX
 SG_ DI_bankAngle : 6|6@1- (0.01,0) [-0.32|0.31] "" XXX
 SG_ DI_chassisControlVideoRequest : 12|4@1+ (1,0) [0|15] "" XXX
 SG_ DI_eepDeliveryBitStatus : 16|1@1+ (1,0) [0|1] "" XXX
 SG_ DI_tireUtilizationRatioFrL : 17|5@1+ (0.0625,0) [0|1.9375] "" XXX
 SG_ DI_tireUtilizationRatioFrR : 22|5@1+ (0.0625,0) [0|1.9375] "" XXX
 SG_ DI_tireUtilizationRatioReL : 27|5@1+ (0.0625,0) [0|1.9375] "" XXX
 SG_ DI_tireUtilizationRatioReR : 32|5@1+ (0.0625,0) [0|1.9375] "" XXX
 SG_ DI_counterSteerTarget : 37|2@1+ (1,0) [0|3] "" XXX
 SG_ DI_splitMuProbability : 39|2@1+ (0.334,0) [0|1.002] "" XXX
 SG_ DI_mzError : 41|2@1+ (1667,0) [0|5001] "" XXX
 SG_ DI_slipDifferenceFrontRear : 43|3@1- (0.133,0) [-0.532|0.399] "" XXX
 SG_ DI_highFreqYawRate : 46|2@1+ (0.334,0) [0|1.002] "" XXX
 SG_ DI_turnDirection : 48|1@1+ (1,0) [0|1] "" XXX
 SG_ DI_absolutePreControlRequest : 49|2@1+ (5000,0) [0|15000] "" XXX
 SG_ DI_oppositeBuildDirFrontAxle : 51|1@1+ (1,0) [0|1] "" XXX
 SG_ DI_oppositeBuildDirRearAxle : 52|1@1+ (1,0) [0|1] "" XXX
 SG_ DI_saturatedEffectiveness : 53|1@1+ (1,0) [0|1] "" XXX
 SG_ DI_driverPanicIndex : 54|2@1+ (0.334,0) [0|1.002] "" XXX
 SG_ DI_learnDownMu : 56|2@1+ (0.334,0) [0|1.002] "" XXX
 SG_ DI_preControlOpposingTurnDir : 58|1@1+ (1,0) [0|1] "" XXX
 SG_ DI_driverFxError : 59|2@1+ (1000,0) [0|3000] "" XXX
 SG_ DI_targetSaturation : 61|3@1+ (0.572,0) [0|4.004] "" XXX

CM_ BO_ 605 "Bytes change when toggling between FSD and AP, as well as Traffic Light and Stop Sign Control in TACC";

CM_ SG_ 659 DAS_autosteerEnabled "1 if Autosteer or FSD is enabled, 0 otherwise";
CM_ SG_ 1160 DAS_steeringControlType "Newer firmware widens this to 3 bits (byte 2 bits 7:5) with 4 = FSD. There, this reads 1 for LANE_KEEP_ASSIST and 2 for FSD";
CM_ SG_ 785 leftBlinkerOn "only describes stalk position if half pressed without auto-cancel blinkers. otherwise acts as expected";
CM_ SG_ 785 rightBlinkerOn "only describes stalk position if half pressed without auto-cancel blinkers. otherwise acts as expected";
CM_ SG_ 785 scrollWheelPressed "captures either scroll wheel left, right or down press";

CM_ BO_ 1161 "Sent by HW3/HW4 Autopilot computers only on firmware with the 3-bit DAS_steeringControlType (not by HW2.5)";
CM_ BO_ 84 "Appears with the 3-bit DAS_steeringControlType firmware on all Autopilot hardware, including HW2.5";
CM_ BO_ 521 "Sent by HW3/HW4 Autopilot computers, not by HW2.5";
CM_ BO_ 2047 "Sent on the party bus by HW3/HW4 cars, not seen on HW2.5";
CM_ SG_ 2047 GTW_dasHw "5 (TESLA_AP4) observed on HW4 cars, not in the source DBC";
CM_ SG_ 1160 DAS_steeringControlType "Legacy firmware only uses the top 2 bits, so its values read shifted left by 1";
CM_ SG_ 880 EPAS3S_driverlessState "Set while the EPS executes an FSD (DAS_steeringControlType 4) request, 3-bit firmware only";
CM_ SG_ 1861 DI_eepDeliveryBitStatus "Set by the update that brought the 3-bit DAS_steeringControlType on most cars (not all), never set on older firmware";
VAL_ 545 VCFRONT_uiAudioLVState 1 "LV_ON" 2 "LV_GOING_DOWN" 3 "LV_FAULT" 0 "LV_OFF" ;
VAL_ 545 VCFRONT_uiHiCurrentLVState 1 "LV_ON" 2 "LV_GOING_DOWN" 3 "LV_FAULT" 0 "LV_OFF" ;
VAL_ 545 VCFRONT_vcrightHiCurrentLVState 1 "LV_ON" 2 "LV_GOING_DOWN" 3 "LV_FAULT" 0 "LV_OFF" ;
VAL_ 545 VCFRONT_vcleftHiCurrentLVState 1 "LV_ON" 2 "LV_GOING_DOWN" 3 "LV_FAULT" 0 "LV_OFF" ;
VAL_ 545 VCFRONT_ocsLVRequest 1 "LV_ON" 2 "LV_GOING_DOWN" 3 "LV_FAULT" 0 "LV_OFF" ;
VAL_ 545 VCFRONT_oilPumpRearLVRequest 1 "LV_ON" 2 "LV_GOING_DOWN" 3 "LV_FAULT" 0 "LV_OFF" ;
VAL_ 545 VCFRONT_oilPumpFrontLVState 1 "LV_ON" 2 "LV_GOING_DOWN" 3 "LV_FAULT" 0 "LV_OFF" ;
VAL_ 545 VCFRONT_disLVState 1 "LV_ON" 2 "LV_GOING_DOWN" 3 "LV_FAULT" 0 "LV_OFF" ;
VAL_ 545 VCFRONT_diLVRequest 1 "LV_ON" 2 "LV_GOING_DOWN" 3 "LV_FAULT" 0 "LV_OFF" ;
VAL_ 545 VCFRONT_das2HighCurrentLVState 1 "LV_ON" 2 "LV_GOING_DOWN" 3 "LV_FAULT" 0 "LV_OFF" ;
VAL_ 545 VCFRONT_das1HighCurrentLVState 1 "LV_ON" 2 "LV_GOING_DOWN" 3 "LV_FAULT" 0 "LV_OFF" ;
VAL_ 545 VCFRONT_amplifierLVRequest 1 "LV_ON" 2 "LV_GOING_DOWN" 3 "LV_FAULT" 0 "LV_OFF" ;
VAL_ 545 VCFRONT_tunerLVRequest 1 "LV_ON" 2 "LV_GOING_DOWN" 3 "LV_FAULT" 0 "LV_OFF" ;
VAL_ 545 VCFRONT_iBoosterLVState 1 "LV_ON" 2 "LV_GOING_DOWN" 3 "LV_FAULT" 0 "LV_OFF" ;
VAL_ 545 VCFRONT_rcmLVRequest 1 "LV_ON" 2 "LV_GOING_DOWN" 3 "LV_FAULT" 0 "LV_OFF" ;
VAL_ 545 VCFRONT_tpmsLVRequest 1 "LV_ON" 2 "LV_GOING_DOWN" 3 "LV_FAULT" 0 "LV_OFF" ;
VAL_ 545 VCFRONT_sccmLVRequest 1 "LV_ON" 2 "LV_GOING_DOWN" 3 "LV_FAULT" 0 "LV_OFF" ;
VAL_ 545 VCFRONT_pcsLVState 1 "LV_ON" 2 "LV_GOING_DOWN" 3 "LV_FAULT" 0 "LV_OFF" ;
VAL_ 545 VCFRONT_ptcLVRequest 1 "LV_ON" 2 "LV_GOING_DOWN" 3 "LV_FAULT" 0 "LV_OFF" ;
VAL_ 545 VCFRONT_hvacCompLVState 1 "LV_ON" 2 "LV_GOING_DOWN" 3 "LV_FAULT" 0 "LV_OFF" ;
VAL_ 545 VCFRONT_tasLVState 1 "LV_ON" 2 "LV_GOING_DOWN" 3 "LV_FAULT" 0 "LV_OFF" ;
VAL_ 545 VCFRONT_hvcLVRequest 1 "LV_ON" 2 "LV_GOING_DOWN" 3 "LV_FAULT" 0 "LV_OFF" ;
VAL_ 545 VCFRONT_radcLVState 1 "LV_ON" 2 "LV_GOING_DOWN" 3 "LV_FAULT" 0 "LV_OFF" ;
VAL_ 545 VCFRONT_epasLVState 1 "LV_ON" 2 "LV_GOING_DOWN" 3 "LV_FAULT" 0 "LV_OFF" ;
VAL_ 545 VCFRONT_espLVState 1 "LV_ON" 2 "LV_GOING_DOWN" 3 "LV_FAULT" 0 "LV_OFF" ;
VAL_ 545 VCFRONT_parkLVState 1 "LV_ON" 2 "LV_GOING_DOWN" 3 "LV_FAULT" 0 "LV_OFF" ;
VAL_ 545 VCFRONT_cpLVRequest 1 "LV_ON" 2 "LV_GOING_DOWN" 3 "LV_FAULT" 0 "LV_OFF" ;
VAL_ 545 VCFRONT_vehiclePowerState 3 "VEHICLE_POWER_STATE_DRIVE" 1 "VEHICLE_POWER_STATE_CONDITIONING" 2 "VEHICLE_POWER_STATE_ACCESSORY" 0 "VEHICLE_POWER_STATE_OFF" ;
VAL_ 545 VCFRONT_LVPowerStateIndex 0 "Mux0" 1 "Mux1" ;
VAL_ 905 DAS_longCollisionWarning 7 "FCM_LONG_COLLISION_WARNING_VEHICLE_CUTIN" 0 "FCM_LONG_COLLISION_WARNING_NONE" 4 "FCM_LONG_COLLISION_WARNING_STOPSIGN_STOPLINE" 9 "FCM_LONG_COLLISION_WARNING_VEHICLE_MCVL2" 15 "FCM_LONG_COLLISION_WARNING_SNA" 8 "FCM_LONG_COLLISION_WARNING_VEHICLE_MCVL" 5 "FCM_LONG_COLLISION_WARNING_TFL_STOPLINE" 2 "FCM_LONG_COLLISION_WARNING_PEDESTRIAN" 12 "FCM_LONG_COLLISION_WARNING_VEHICLE_CIPV2" 6 "FCM_LONG_COLLISION_WARNING_VEHICLE_CIPV" 10 "FCM_LONG_COLLISION_WARNING_VEHICLE_MCVR" 3 "FCM_LONG_COLLISION_WARNING_IPSO" 1 "FCM_LONG_COLLISION_WARNING_VEHICLE_UNKNOWN" 11 "FCM_LONG_COLLISION_WARNING_VEHICLE_MCVR2" ;
VAL_ 905 DAS_ppOffsetDesiredRamp 128 "PP_NO_OFFSET" ;
VAL_ 905 DAS_driverInteractionLevel 0 "DRIVER_INTERACTING" 1 "DRIVER_NOT_INTERACTING" 2 "CONTINUED_DRIVER_NOT_INTERACTING" ;
VAL_ 905 DAS_robState 0 "ROB_STATE_INHIBITED" 2 "ROB_STATE_ACTIVE" 3 "ROB_STATE_MAPLESS" 1 "ROB_STATE_MEASURE" ;
VAL_ 905 DAS_radarTelemetry 0 "RADAR_TELEMETRY_IDLE" 1 "RADAR_TELEMETRY_NORMAL" 2 "RADAR_TELEMETRY_URGENT" ;
VAL_ 905 DAS_lssState 7 "LSS_STATE_OFF" 1 "LSS_STATE_LDW" 4 "LSS_STATE_MONITOR" 2 "LSS_STATE_LKA" 3 "LSS_STATE_ELK" 0 "LSS_STATE_FAULT" 5 "LSS_STATE_BLINDSPOT" 6 "LSS_STATE_ABORT" ;
VAL_ 905 DAS_ACC_report 12 "ACC_REPORT_LC_EXTERNAL_STATE_ABORTING" 17 "ACC_REPORT_TARGET_MCP" 11 "ACC_REPORT_LC_HANDS_ON_REQD_STRUCK_OUT" 19 "ACC_REPORT_MCVLR_DPP" 1 "ACC_REPORT_TARGET_CIPV" 15 "ACC_REPORT_RADAR_OBJ_ONE" 16 "ACC_REPORT_RADAR_OBJ_TWO" 14 "ACC_REPORT_LC_EXTERNAL_STATE_ACTIVE_RESTRICTED" 4 "ACC_REPORT_TARGET_MCVR" 20 "ACC_REPORT_MCVLR_IN_PATH" 10 "ACC_REPORT_CSA" 5 "ACC_REPORT_TARGET_CUTIN" 9 "ACC_REPORT_TARGET_TYPE_FAULT" 7 "ACC_REPORT_TARGET_TYPE_TRAFFIC_LIGHT" 6 "ACC_REPORT_TARGET_TYPE_STOP_SIGN" 24 "ACC_REPORT_BEHAVIOR_REPORT" 18 "ACC_REPORT_FLEET_SPEEDS" 2 "ACC_REPORT_TARGET_IN_FRONT_OF_CIPV" 23 "ACC_REPORT_CAMERA_ONLY" 3 "ACC_REPORT_TARGET_MCVL" 22 "ACC_REPORT_RADAR_OBJ_FIVE" 0 "ACC_REPORT_TARGET_NONE" 8 "ACC_REPORT_TARGET_TYPE_IPSO" 21 "ACC_REPORT_CIPV_CUTTING_OUT" 13 "ACC_REPORT_LC_EXTERNAL_STATE_ABORTED" ;
VAL_ 905 DAS_pmmCameraFaultReason 1 "PMM_CAMERA_BLOCKED_FRONT" 2 "PMM_CAMERA_INVALID_MIA" 0 "PMM_CAMERA_NO_FAULT" ;
VAL_ 905 DAS_pmmSysFaultReason 4 "PMM_FAULT_STEERING_ANGLE_RATE" 6 "PMM_FAULT_ROAD_TYPE" 5 "PMM_FAULT_DISABLED_BY_USER" 0 "PMM_FAULT_NONE" 1 "PMM_FAULT_DAS_DISABLED" 3 "PMM_FAULT_DI_FAULT" 2 "PMM_FAULT_SPEED" 7 "PMM_FAULT_BRAKE_PEDAL_INHIBIT" ;
VAL_ 905 DAS_pmmRadarFaultReason 2 "PMM_RADAR_INVALID_MIA" 1 "PMM_RADAR_BLOCKED_FRONT" 0 "PMM_RADAR_NO_FAULT" ;
VAL_ 905 DAS_pmmUltrasonicsFaultReason 2 "PMM_ULTRASONICS_BLOCKED_REAR" 0 "PMM_ULTRASONICS_NO_FAULT" 1 "PMM_ULTRASONICS_BLOCKED_FRONT" 3 "PMM_ULTRASONICS_BLOCKED_BOTH" 4 "PMM_ULTRASONICS_INVALID_MIA" ;
VAL_ 905 DAS_activationFailureStatus 0 "LC_ACTIVATION_IDLE" 2 "LC_ACTIVATION_FAILED_2" 1 "LC_ACTIVATION_FAILED_1" ;
VAL_ 905 DAS_pmmLoggingRequest 0 "FALSE" 1 "TRUE" ;
VAL_ 905 DAS_pmmObstacleSeverity 5 "PMM_CRASH_FRONT" 0 "PMM_NONE" 2 "PMM_IMMINENT_FRONT" 4 "PMM_CRASH_REAR" 1 "PMM_IMMINENT_REAR" 6 "PMM_ACCEL_LIMIT" 7 "PMM_SNA" 3 "PMM_BRAKE_REQUEST" ;
VAL_ 905 DAS_accSpeedLimit 1023 "SNA" 0 "NONE" ;
VAL_ 264 DI_axleSpeed -32768 "SNA" ;
VAL_ 264 DI_torqueActual -4096 "SNA" ;
VAL_ 264 DI_torqueCommand -4096 "SNA" ;
VAL_ 585 SCCM_turnIndicatorStalkStatus 3 "DOWN_1" 5 "SNA" 0 "IDLE" 1 "UP_1" 4 "DOWN_2" 2 "UP_2" ;
VAL_ 585 SCCM_washWipeButtonStatus 3 "SNA" 0 "NOT_PRESSED" 2 "2ND_DETENT" 1 "1ST_DETENT" ;
VAL_ 585 SCCM_highBeamStalkStatus 3 "SNA" 0 "IDLE" 1 "PULL" 2 "PUSH" ;
VAL_ 280 DI_trackModeState 0 "TRACK_MODE_UNAVAILABLE" 1 "TRACK_MODE_AVAILABLE" 2 "TRACK_MODE_ON" ;
VAL_ 280 DI_keepAliveRequest 1 "KEEP_ALIVE" 0 "NO_REQUEST" ;
VAL_ 280 DI_epbRequest 0 "DI_EPBREQUEST_NO_REQUEST" 1 "DI_EPBREQUEST_PARK" 2 "DI_EPBREQUEST_UNPARK" ;
VAL_ 280 DI_tractionControlMode 0 "TC_NORMAL" 1 "TC_SLIP_START" 4 "TC_ROLLS_MODE" 2 "TC_DEV_MODE_1" 5 "TC_DYNO_MODE" 3 "TC_DEV_MODE_2" ;
VAL_ 280 DI_accelPedalPos 255 "SNA" ;
VAL_ 280 DI_immobilizerState 2 "DI_IMM_STATE_AUTHENTICATING" 0 "DI_IMM_STATE_INIT_SNA" 3 "DI_IMM_STATE_DISARMED" 4 "DI_IMM_STATE_IDLE" 6 "DI_IMM_STATE_FAULT" 1 "DI_IMM_STATE_REQUEST" 5 "DI_IMM_STATE_RESET" ;
VAL_ 280 DI_gear 1 "DI_GEAR_P" 0 "DI_GEAR_INVALID" 7 "DI_GEAR_SNA" 2 "DI_GEAR_R" 3 "DI_GEAR_N" 4 "DI_GEAR_D" ;
VAL_ 280 DI_brakePedalState 2 "INVALID" 0 "OFF" 1 "ON" ;
VAL_ 280 DI_systemState 5 "DI_SYS_ENABLE" 1 "DI_SYS_IDLE" 2 "DI_SYS_STANDBY" 0 "DI_SYS_UNAVAILABLE" 3 "DI_SYS_FAULT" 4 "DI_SYS_ABORT" ;
VAL_ 605 DAS_trafficLightColor 0 "NONE" 1 "RED" 2 "GREEN" 3 "YELLOW" ;
VAL_ 697 DAS_accelMax 511 "SNA" ;
VAL_ 697 DAS_accelMin 511 "SNA" ;
VAL_ 697 DAS_jerkMax 255 "SNA" ;
VAL_ 697 DAS_jerkMin 511 "SNA" ;
VAL_ 697 DAS_aebEvent 2 "AEB_FAULT" 0 "AEB_NOT_ACTIVE" 3 "AEB_SNA" 1 "AEB_ACTIVE" ;
VAL_ 697 DAS_accState 4 "ACC_ON" 9 "APC_PAUSE" 14 "ACC_CANCEL_OUT_OF_CALIBRATION" 10 "APC_UNPARK_COMPLETE" 6 "APC_FORWARD" 3 "ACC_HOLD" 2 "ACC_CANCEL_RADAR_BLIND" 7 "APC_COMPLETE" 1 "ACC_CANCEL_CAMERA_BLIND" 8 "APC_ABORT" 13 "ACC_CANCEL_GENERIC_SILENT" 5 "APC_BACKWARD" 11 "APC_SELFPARK_START" 0 "ACC_CANCEL_GENERIC" 12 "ACC_CANCEL_PATH_NOT_CLEAR" 15 "FAULT_SNA" ;
VAL_ 697 DAS_setSpeed 4095 "SNA" ;
VAL_ 341 ESP_vehicleSpeed 1023 "ESP_VEHICLE_SPEED_SNA" ;
VAL_ 341 ESP_vehicleStandstillSts 1 "STANDSTILL" 0 "NOT_STANDSTILL" ;
VAL_ 341 ESP_wheelSpeedsQF 0 "ONE_OR_MORE_WSS_INVALID" 1 "ALL_WSS_VALID" ;
VAL_ 341 ESP_WheelRotationFrL 1 "WR_BACKWARD" 0 "WR_FORWARD" 3 "WR_NOT_DEFINABLE" 2 "WR_STANDSTILL" ;
VAL_ 341 ESP_WheelRotationFrR 1 "WR_BACKWARD" 0 "WR_FORWARD" 3 "WR_NOT_DEFINABLE" 2 "WR_STANDSTILL" ;
VAL_ 341 ESP_WheelRotationReL 1 "WR_BACKWARD" 0 "WR_FORWARD" 3 "WR_NOT_DEFINABLE" 2 "WR_STANDSTILL" ;
VAL_ 341 ESP_WheelRotationReR 1 "WR_BACKWARD" 0 "WR_FORWARD" 3 "WR_NOT_DEFINABLE" 2 "WR_STANDSTILL" ;
VAL_ 341 ESP_wheelPulseCountReR 255 "SNA" ;
VAL_ 341 ESP_wheelPulseCountReL 255 "SNA" ;
VAL_ 341 ESP_wheelPulseCountFrR 255 "SNA" ;
VAL_ 341 ESP_wheelPulseCountFrL 255 "SNA" ;
VAL_ 969 APS_apbGpioState 0 "AP_GPIO_STATE_PWR_DOWN_REBOOT" 3 "AP_GPIO_STATE_HEALTHY" 1 "AP_GPIO_STATE_DISABLED" 2 "AP_GPIO_STATE_CRITICAL" ;
VAL_ 969 APS_apbStatusMonitorState 1 "STATUS_MONITOR_STATE_PWR_OFF" 2 "STATUS_MONITOR_STATE_INIT" 7 "STATUS_MONITOR_NUM_STATES" 0 "STATUS_MONITOR_STATE_UNKNOWN" 4 "STATUS_MONITOR_STATE_CRITICAL" 6 "STATUS_MONITOR_STATE_RECOVERY" 5 "STATUS_MONITOR_STATE_SHUTTING_DOWN" 3 "STATUS_MONITOR_STATE_NOMINAL" ;
VAL_ 969 APS_eacInternalState 1 "APS_EAC_STATE_MOMENTARY" 3 "APS_EAC_STATE_AUTOPARK" 5 "APS_EAC_STATE_OVERRIDE" 4 "APS_EAC_STATE_INHIBIT" 0 "APS_EAC_STATE_INIT" 2 "APS_EAC_STATE_CONTINUOUS" 7 "APS_EAC_NUM_STATES" 6 "APS_EAC_STATE_LSS" ;
VAL_ 969 APS_appGpioState 0 "AP_GPIO_STATE_PWR_DOWN_REBOOT" 3 "AP_GPIO_STATE_HEALTHY" 1 "AP_GPIO_STATE_DISABLED" 2 "AP_GPIO_STATE_CRITICAL" ;
VAL_ 969 APS_canMaster 0 "CAN_MASTER_APS" 2 "CAN_MASTER_APB" 3 "CAN_MASTER_SNA" 1 "CAN_MASTER_APP" ;
VAL_ 969 APS_vehBehaviorState 0 "VEH_BEHAVIOR_STATE_UNKNOWN" 3 "VEH_BEHAVIOR_STATE_APS_BRIDGE_APP" 1 "VEH_BEHAVIOR_STATE_APS_AVAILABLE" 5 "VEH_BEHAVIOR_STATE_APS_FAIL_SAFE" 7 "VEH_BEHAVIOR_NUM_STATES" 2 "VEH_BEHAVIOR_STATE_APS_CONTROL" 6 "VEH_BEHAVIOR_STATE_APS_OVERRIDE" 4 "VEH_BEHAVIOR_STATE_APS_BRIDGE_APB" ;
VAL_ 969 APS_appStatusMonitorState 1 "STATUS_MONITOR_STATE_PWR_OFF" 2 "STATUS_MONITOR_STATE_INIT" 7 "STATUS_MONITOR_NUM_STATES" 0 "STATUS_MONITOR_STATE_UNKNOWN" 4 "STATUS_MONITOR_STATE_CRITICAL" 6 "STATUS_MONITOR_STATE_RECOVERY" 5 "STATUS_MONITOR_STATE_SHUTTING_DOWN" 3 "STATUS_MONITOR_STATE_NOMINAL" ;
VAL_ 925 IBST_internalState 5 "TRANSITION_TO_IDLE" 0 "NO_MODE_ACTIVE" 4 "DIAGNOSTIC" 6 "POST_DRIVE_CHECK" 1 "PRE_DRIVE_CHECK" 3 "EXTERNAL_BRAKE_REQUEST" 2 "LOCAL_BRAKE_REQUEST" ;
VAL_ 925 IBST_driverBrakeApply 1 "BRAKES_NOT_APPLIED" 2 "DRIVER_APPLYING_BRAKES" 3 "FAULT" 0 "NOT_INIT_OR_OFF" ;
VAL_ 925 IBST_iBoosterStatus 6 "IBOOSTER_ACTUATION" 4 "IBOOSTER_ACTIVE_GOOD_CHECK" 2 "IBOOSTER_FAILURE" 5 "IBOOSTER_READY" 3 "IBOOSTER_DIAGNOSTIC" 0 "IBOOSTER_OFF" 1 "IBOOSTER_INIT" ;
VAL_ 880 EPAS3S_eacStatus 0 "INHIBITED" 1 "AVAILABLE" 2 "ACTIVE" 3 "FAULT" 4 "LKA_ELK_AVAILABLE" 5 "LKA_ACTIVE" 6 "ELK_AVAILABLE" 7 "ELK_ACTIVE" ;
VAL_ 880 EPAS3S_handsOnLevel 1 "LEVEL_1" 0 "LEVEL_0" 3 "LEVEL_3" 2 "LEVEL_2" ;
VAL_ 880 EPAS3S_torsionBarTorque 4095 "SNA" 4094 "UNDEFINABLE_DATA" ;
VAL_ 880 EPAS3S_eacErrorCode 15 "SNA" 11 "EAC_ERROR_HIGH_TORSION_SAFETY" 4 "EAC_ERROR_TMP_FAULT" 2 "EAC_ERROR_MAX_SPEED" 7 "EAC_ERROR_HIGH_ANGLE_RATE_REQ" 0 "EAC_ERROR_IDLE" 10 "EAC_ERROR_HIGH_MMOT_SAFETY" 6 "EAC_ERROR_HIGH_ANGLE_REQ" 8 "EAC_ERROR_HIGH_ANGLE_SAFETY" 5 "EAR_ERROR_MAX_STEER_DELTA" 13 "EAC_ERROR_PINION_VEL_DIFF" 1 "EAC_ERROR_MIN_SPEED" 14 "EAC_EXTERNAL_MONITOR_INHIBIT" 12 "EAC_ERROR_LOW_ASSIST" 9 "EAC_ERROR_HIGH_ANGLE_RATE_SAFETY" 3 "EAC_ERROR_HANDS_ON" ;
VAL_ 880 EPAS3S_steeringRackForce 1023 "SNA" 1022 "NOT_IN_SPEC" ;
VAL_ 880 EPAS3S_steeringFault 0 "NO_FAULT" 1 "FAULT" ;
VAL_ 880 EPAS3S_steeringReduced 0 "NORMAL_ASSIST" 1 "REDUCED_ASSIST" ;
VAL_ 880 EPAS3S_internalSASQF 1 "IN_SPEC" 0 "UNDEFINABLE_ACCURACY" ;
VAL_ 880 EPAS3S_currentTuneMode 3 "STEERING_TUNE_RWD_COMFORT" 1 "STEERING_TUNE_DM_STANDARD" 5 "STEERING_TUNE_RWD_SPORT" 0 "STEERING_TUNE_DM_COMFORT" 4 "STEERING_TUNE_RWD_STANDARD" 2 "STEERING_TUNE_DM_SPORT" ;
VAL_ 599 DI_uiSpeedUnits 0 "DI_SPEED_MPH" 1 "DI_SPEED_KPH" ;
VAL_ 599 DI_uiSpeed 255 "DI_UI_SPEED_SNA" ;
VAL_ 599 DI_vehicleSpeed 4095 "SNA" ;
VAL_ 637 APS_eacAllow 0 "INHIBIT" 1 "ALLOW" 2 "RESERVED" 3 "SNA";
VAL_ 1160 DAS_steeringControlType 0 "NONE" 1 "ANGLE_CONTROL" 2 "LANE_KEEP_ASSIST" 3 "EMERGENCY_LANE_KEEP" 4 "FSD" ;
VAL_ 1160 DAS_steeringAngleRequest 16384 "ZERO_ANGLE" ;
VAL_ 297 SCCM_steeringAngleValidity 3 "SNA" 2 "INIT" 0 "INVALID" 1 "VALID" ;
VAL_ 297 SCCM_steeringAngleSensorStatus 0 "OK" 1 "INIT" 2 "ERROR" 3 "ERROR_INIT" ;
VAL_ 646 DI_rollPreventionState 0 "UNAVAILABLE" 1 "STANDBY" 2 "READY" 3 "BUILD" 4 "HOLD" 5 "PARK" 6 "FAULT" 7 "INIT" ;
VAL_ 646 DI_vehicleHoldState 0 "UNAVAILABLE" 1 "STANDBY" 2 "BLEND_IN" 3 "STANDSTILL" 4 "BLEND_OUT" 5 "PARK" 6 "FAULT" 7 "INIT" ;
VAL_ 646 DI_pmmStatus 0 "INACTIVE" 1 "ACTIVE" 2 "LOGGING_ACTIVE" 3 "SNA" ;
VAL_ 646 DI_aebState 0 "UNAVAILABLE" 1 "STANDBY" 2 "ENABLED" 3 "STANDSTILL" 4 "FAULT" 7 "SNA" ;
VAL_ 646 DI_autopilotRequest 0 "IDLE" 1 "ACTIVATE" ;
VAL_ 646 DI_parkBrakeState 0 "UNAVAILABLE" 1 "RELEASED" 2 "REQUESTED" 3 "APPLIED" 4 "FAULTED" 5 "PANIC_EPB" 6 "PANIC_SKID" 7 "RELEASING" 15 "SNA" ;
VAL_ 646 DI_autoparkState 0 "UNAVAILABLE" 1 "STANDBY" 2 "STARTED" 3 "ACTIVE" 4 "COMPLETE" 5 "PAUSED" 6 "ABORTED" 7 "RESUMED" 8 "UNPARK_COMPLETE" 9 "SELFPARK_STARTED" 15 "SNA" ;
VAL_ 646 DI_speedUnits 0 "MPH" 1 "KPH" ;
VAL_ 646 DI_cruiseState 0 "UNAVAILABLE" 1 "STANDBY" 2 "ENABLED" 3 "STANDSTILL" 4 "OVERRIDE" 5 "FAULT" 6 "PRE_FAULT" 7 "PRE_CANCEL" ;
VAL_ 659 DAS_driverSteeringWeight 0 "light" 1 "standard" 2 "heavy";
VAL_ 659 DAS_offRoadAssist 0 "disabled" 3 "enabled";
VAL_ 659 DAS_distanceUnits 1 "miles" 0 "kilometers";
VAL_ 659 DAS_fcwSensitivity 0 "early" 1 "medium" 2 "late" 3 "off";
VAL_ 659 DAS_driverAccelerationMode 0 "chill" 1 "standard";
VAL_ 785 buckleStatus 1 "LATCHED" 0 "UNLATCHED" ;
VAL_ 785 anyDoorOpen 1 "OPEN" 0 "CLOSED" ;
VAL_ 785 leftBlinkerBlinking 0 "off" 1 "blinking, off" 2 "blinking, on";
VAL_ 785 rightBlinkerBlinking 0 "off" 1 "blinking, off" 2 "blinking, on";
VAL_ 923 DAS_autoLaneChangeState 5 "ALC_UNAVAILABLE_VEHICLE_SPEED" 17 "ALC_ABORT_POOR_VIEW_RANGE" 23 "ALC_BLOCKED_VEH_TTC_AND_USS_L" 0 "ALC_UNAVAILABLE_DISABLED" 26 "ALC_BLOCKED_LANE_TYPE_L" 29 "ALC_ABORT_TIMEOUT" 9 "ALC_IN_PROGRESS_L" 4 "ALC_UNAVAILABLE_EXITING_HIGHWAY" 22 "ALC_BLOCKED_VEH_TTC_L" 12 "ALC_WAITING_FOR_SIDE_OBST_TO_PASS_R" 18 "ALC_ABORT_LC_HEALTH_BAD" 28 "ALC_WAITING_HANDS_ON" 8 "ALC_AVAILABLE_BOTH" 11 "ALC_WAITING_FOR_SIDE_OBST_TO_PASS_L" 3 "ALC_UNAVAILABLE_TP_FOLLOW" 2 "ALC_UNAVAILABLE_SONICS_INVALID" 21 "ALC_UNAVAILABLE_SOLID_LANE_LINE" 24 "ALC_BLOCKED_VEH_TTC_R" 1 "ALC_UNAVAILABLE_NO_LANES" 25 "ALC_BLOCKED_VEH_TTC_AND_USS_R" 30 "ALC_ABORT_MISSION_PLAN_INVALID" 27 "ALC_BLOCKED_LANE_TYPE_R" 19 "ALC_ABORT_BLINKER_TURNED_OFF" 31 "ALC_SNA" 13 "ALC_WAITING_FOR_FWD_OBST_TO_PASS_L" 16 "ALC_ABORT_SIDE_OBSTACLE_PRESENT_R" 6 "ALC_AVAILABLE_ONLY_L" 20 "ALC_ABORT_OTHER_REASON" 15 "ALC_ABORT_SIDE_OBSTACLE_PRESENT_L" 7 "ALC_AVAILABLE_ONLY_R" 14 "ALC_WAITING_FOR_FWD_OBST_TO_PASS_R" 10 "ALC_IN_PROGRESS_R" ;
VAL_ 923 DAS_autopilotHandsOnState 8 "LC_HANDS_ON_SUSPENDED" 15 "LC_HANDS_ON_SNA" 7 "LC_HANDS_ON_REQD_STRUCK_OUT" 3 "LC_HANDS_ON_REQD_VISUAL" 4 "LC_HANDS_ON_REQD_CHIME_1" 6 "LC_HANDS_ON_REQD_SLOWING" 1 "LC_HANDS_ON_REQD_DETECTED" 2 "LC_HANDS_ON_REQD_NOT_DETECTED" 5 "LC_HANDS_ON_REQD_CHIME_2" 0 "LC_HANDS_ON_NOT_REQD" ;
VAL_ 923 DAS_fleetSpeedState 0 "FLEETSPEED_UNAVAILABLE" 1 "FLEETSPEED_AVAILABLE" 2 "FLEETSPEED_ACTIVE" 3 "FLEETSPEED_HOLD" ;
VAL_ 923 DAS_laneDepartureWarning 5 "SNA" 0 "NONE" 2 "RIGHT_WARNING" 4 "RIGHT_WARNING_SEVERE" 3 "LEFT_WARNING_SEVERE" 1 "LEFT_WARNING" ;
VAL_ 923 DAS_csaState 1 "CSA_EXTERNAL_STATE_AVAILABLE" 3 "CSA_EXTERNAL_STATE_HOLD" 2 "CSA_EXTERNAL_STATE_ENABLE" 0 "CSA_EXTERNAL_STATE_UNAVAILABLE" ;
VAL_ 923 DAS_sideCollisionInhibit 0 "NO_INHIBIT" 1 "INHIBIT" ;
VAL_ 923 DAS_sideCollisionWarning 0 "NONE" 2 "WARN_RIGHT" 1 "WARN_LEFT" 3 "WARN_LEFT_RIGHT" ;
VAL_ 923 DAS_sideCollisionAvoid 3 "SNA" 0 "NONE" 1 "AVOID_LEFT" 2 "AVOID_RIGHT" ;
VAL_ 923 DAS_autoparkReady 0 "AUTOPARK_UNAVAILABLE" 1 "AUTOPARK_READY" ;
VAL_ 923 DAS_forwardCollisionWarning 3 "SNA" 0 "NONE" 1 "FORWARD_COLLISION_WARNING" ;
VAL_ 923 DAS_heaterState 0 "HEATER_OFF_SNA" 1 "HEATER_ON" ;
VAL_ 923 DAS_visionOnlySpeedLimit 31 "NONE" 0 "UNKNOWN_SNA" ;
VAL_ 923 DAS_suppressSpeedWarning 1 "Suppress_Speed_Warning" 0 "Do_Not_Suppress" ;
VAL_ 923 DAS_fusedSpeedLimit 31 "NONE" 0 "UNKNOWN_SNA" ;
VAL_ 923 DAS_blindSpotRearRight 3 "SNA" 0 "NO_WARNING" 1 "WARNING_LEVEL_1" 2 "WARNING_LEVEL_2" ;
VAL_ 923 DAS_blindSpotRearLeft 3 "SNA" 0 "NO_WARNING" 1 "WARNING_LEVEL_1" 2 "WARNING_LEVEL_2" ;
VAL_ 923 DAS_autopilotState 15 "SNA" 8 "ABORTING" 3 "ACTIVE_NOMINAL" 0 "DISABLED" 4 "ACTIVE_RESTRICTED" 5 "ACTIVE_NAV" 6 "ACTIVE_FSD" 14 "FAULT" 1 "UNAVAILABLE" 9 "ABORTED" 2 "AVAILABLE" ;
VAL_ 325 ESP_absBrakeEvent2 0 "NOT_ACTIVE" 1 "ACTIVE_FRONT_REAR" 2 "ACTIVE_FRONT" 3 "ACTIVE_REAR";
VAL_ 325 ESP_absFaultLamp 0 "OFF" 1 "ON";
VAL_ 325 ESP_brakeApply 0 "INACTIVE" 1 "ACTIVE";
VAL_ 325 ESP_brakeDiscWipingActive 0 "INACTIVE" 1 "ACTIVE";
VAL_ 325 ESP_brakeLamp 0 "OFF" 1 "ON";
VAL_ 325 ESP_brakeTorqueTarget 8191 "SNA";
VAL_ 325 ESP_btcTargetState 0 "OFF" 1 "BACKUP" 2 "ON" 3 "SNA";
VAL_ 325 ESP_cdpStatus 0 "CDP_IS_NOT_AVAILABLE" 1 "CDP_IS_AVAILABLE" 2 "ACTUATING_EPB_CDP" 3 "CDP_COMMAND_INVALID";
VAL_ 325 ESP_driverBrakeApply 0 "NotInit_orOff" 1 "Not_Applied" 2 "Driver_applying_brakes" 3 "Faulty_SNA";
VAL_ 325 ESP_ebdFaultLamp 0 "OFF" 1 "ON";
VAL_ 325 ESP_ebrStandstillSkid 0 "NO_STANDSTILL_SKID" 1 "STANDSTILL_SKID_DETECTED";
VAL_ 325 ESP_ebrStatus 0 "EBR_IS_NOT_AVAILABLE" 1 "EBR_IS_AVAILABLE" 2 "ACTUATING_DI_EBR" 3 "EBR_COMMAND_INVALID";
VAL_ 325 ESP_espFaultLamp 0 "OFF" 1 "ON";
VAL_ 325 ESP_espLampFlash 0 "OFF" 1 "FLASH";
VAL_ 325 ESP_espModeActive 0 "00_NORMAL" 1 "01" 2 "02" 3 "03";
VAL_ 325 ESP_lateralAccelQF 0 "UNDEFINABLE_ACCURACY" 1 "IN_SPEC";
VAL_ 325 ESP_longitudinalAccelQF 0 "UNDEFINABLE_ACCURACY" 1 "IN_SPEC";
VAL_ 325 ESP_ptcTargetState 0 "FAULT" 1 "BACKUP" 2 "ON" 3 "SNA";
VAL_ 325 ESP_stabilityControlSts2 0 "INIT" 1 "ON" 2 "ENGAGED" 3 "FAULTED";
VAL_ 325 ESP_steeringAngleQF 0 "UNDEFINABLE_ACCURACY" 1 "IN_SPEC";
VAL_ 325 ESP_yawRateQF 0 "UNDEFINABLE_ACCURACY" 1 "IN_SPEC";
VAL_ 84 DI_ah_vehicleSpeedLimit 511 "SNA" ;
VAL_ 521 DAS_gearRequest 0 "IDLE_SNA" 1 "PARK" 2 "REVERSE" 3 "NEUTRAL" 4 "DRIVE" ;
VAL_ 521 DAS_pedalControl_accelPedalPos 255 "SNA" ;
VAL_ 2047 GTW_deliveryStatus 0 "NOT_DELIVERED" 1 "DELIVERED" ;
VAL_ 2047 GTW_exteriorTrimType 0 "STANDARD_CHROME" 1 "SATIN_BLACK" ;
VAL_ 2047 GTW_gloveboxUSBType 1 "TSC_USB3_A" ;
VAL_ 2047 GTW_mapRegion 0 "US" 1 "EU" 2 "NONE" 3 "CN" 4 "AU" 5 "JP" 6 "TW" 7 "KR" 8 "ME" 9 "HK" 10 "MO" 11 "SE" ;
VAL_ 2047 GTW_frontSeatHeaters 0 "NONE" 1 "KONGSBERG_LOW_POWER" ;
VAL_ 2047 GTW_cabinPTCHeaterType 1 "NONE" ;
VAL_ 2047 GTW_coolantPumpType 3 "SM6PHAN_OFFBOARD4PSAN" 5 "DUAL_MIX" ;
VAL_ 2047 GTW_rearSeatHeaters 0 "NONE" 1 "KONGSBERG_LOW_POWER" ;
VAL_ 2047 GTW_rightHandDrive 0 "LEFT" 1 "RIGHT" ;
VAL_ 2047 GTW_eCallAntennaHW 0 "BACKUP_OR_MAIN_ANT" 1 "MAIN_ANT_ONLY" ;
VAL_ 2047 GTW_performancePackage 0 "BASE" ;
VAL_ 2047 GTW_rearLightType 0 "NA" 2 "GLOBAL" ;
VAL_ 2047 GTW_compressorType 2 "41CC_11K" 4 "11K_COP1_ENABLED" ;
VAL_ 2047 GTW_epblHwType 6 "MANDO_P2" ;
VAL_ 2047 GTW_homelinkType 0 "NONE" 1 "HOMELINK_V_OPT_2" ;
VAL_ 2047 GTW_powerSteeringColumn 0 "NOT_INSTALLED" 1 "TK" ;
VAL_ 2047 GTW_headlamps 1 "PREMIUM" 2 "GLOBAL" ;
VAL_ 2047 GTW_vdcType 0 "BOSCH_VDC" 1 "TESLA_VDC" ;
VAL_ 2047 GTW_epbrHwType 6 "MANDO_P2" ;
VAL_ 2047 GTW_memoryMirrors 0 "NOT_INSTALLED" 1 "SMR" ;
VAL_ 2047 GTW_twelveVBatteryType 2 "CATL_LI_ION" ;
VAL_ 2047 GTW_chassisType 0 "S_CHASSIS" 1 "X_CHASSIS" ;
VAL_ 2047 GTW_powerLiftgateType 0 "NOT_INSTALLED" 1 "TESLA_REV1" ;
VAL_ 2047 GTW_lumbarECUType 0 "NONE" 1 "ALFMEIER" ;
VAL_ 2047 GTW_blowerMotorType 0 "SHINANO" 1 "DELTA" ;
VAL_ 2047 GTW_airSuspension 2 "TESLA_ADAPTIVE" ;
VAL_ 2047 GTW_immersiveAudio 2 "PREMIUM" ;
VAL_ 2047 GTW_autopilotCameraType 0 "RCCB_CAMERAS" ;
VAL_ 2047 GTW_auxParkLamps 1 "NA_PREMIUM" 2 "EU" ;
VAL_ 2047 GTW_passengerOccupancySensorType 2 "IEE_OCS" ;
VAL_ 2047 GTW_connectivityPackage 0 "BASE" 1 "PREMIUM" ;
VAL_ 2047 GTW_frontUsbHubType 0 "2" 4 "NO_DATA" ;
VAL_ 2047 GTW_plcSupportType 0 "NONE" 1 "ONBOARD_ADAPTER" 2 "NATIVE_CHARGE_PORT" ;
VAL_ 2047 GTW_gloveboxActuatorType 0 "SOLENOID" 1 "SMA" ;
VAL_ 2047 GTW_hvacPanelVaneType 0 "PARALLEL_V1" 1 "CONVERGENT_V1" ;
VAL_ 2047 GTW_badgingVersion 0 "0" 1 "1" ;
VAL_ 2047 GTW_superManifoldType 0 "TYPE0" 1 "TYPE1" 2 "TYPE2" ;
VAL_ 2047 GTW_eBuckConfig 0 "NONE" 1 "DEV_BUCK" ;
VAL_ 2047 GTW_epasType 1 "MANDO_VGR66_GEN3" ;
VAL_ 2047 GTW_packEnergy 3 "P2" ;
VAL_ 2047 GTW_tireType 0 "UNKNOWN" 1 "MICHELIN_ALL_SEASON_18" 2 "MICHELIN_SUMMER_18" 3 "HANKOOK_SUMMER_19" 4 "CONTI_ALL_SEASON_19" 5 "MICHELIN_SUMMER_20" 17 "GOODYEAR_ALL_SEASON_20" 18 "PIRELLI_SUMMER_21" 19 "MICHELIN_ALL_SEASON_21" 20 "PIRELLI_SUMMER_19" 21 "PIRELLI_SUMMER_20" 22 "MICHELIN_SUMMER_21" 23 "CONTI_ALL_SEASON_20" 24 "CONTI_SUMMER_22" 25 "PIRELLI_ALL_SEASON_22" 26 "HANKOOK_ALL_SEASON_18" ;
VAL_ 2047 GTW_steeringHeaterEnabled 0 "DISABLED" 1 "ENABLED" ;
VAL_ 2047 GTW_activeHighBeam 0 "NOT_ACTIVE" 1 "ACTIVE" ;
VAL_ 2047 GTW_airbagCutoffSwitch 0 "DISABLED" 1 "ENABLED" ;
VAL_ 2047 GTW_frontFogLamps 0 "NOT_INSTALLED" 1 "INSTALLED" ;
VAL_ 2047 GTW_intrusionSensorType 0 "NOT_INSTALLED" 1 "VODAFONE" ;
VAL_ 2047 GTW_audioType 1 "PREMIUM" ;
VAL_ 2047 GTW_frontSeatReclinerHardware 0 "STANDARD_RANGE" 1 "RIGHT_SEAT_REDUCED_RANGE" 2 "LEFT_SEAT_REDUCED_RANGE" 3 "LEFT_RIGHT_SEAT_REDUCED_RANGE" ;
VAL_ 2047 GTW_spoilerType 0 "NOT_INSTALLED" 1 "PASSIVE" ;
VAL_ 2047 GTW_hornType 0 "TRUMPET" 1 "EXT_SPEAKER_V2" ;
VAL_ 2047 GTW_roofGlassType 0 "TSA3_PET" 1 "TSA5_NOPET" ;
VAL_ 2047 GTW_brakeLineSwitchType 0 "DI_VC_SHARED" 1 "VC_ONLY" ;
VAL_ 2047 GTW_interiorCameraType 1 "VD6763" ;
VAL_ 2047 GTW_rearFogLamps 0 "NOT_INSTALLED" 1 "INSTALLED" ;
VAL_ 2047 GTW_dasHw 3 "PARKER_PASCAL_2_5" 4 "TESLA_AP3" 5 "TESLA_AP4" ;
VAL_ 2047 GTW_eCallEnabled 0 "DISABLED" 1 "ENABLED_OHC_SOS" 2 "ENABLED_UI_SOS" ;
VAL_ 2047 GTW_espValveType 0 "UNKNOWN" 1 "VALVE_TYPE_1" 2 "VALVE_TYPE_2" ;
VAL_ 2047 GTW_roofType 1 "FIXED_GLASS" ;
VAL_ 2047 GTW_autopilot 0 "NONE" 1 "HIGHWAY" 2 "ENHANCED" 3 "SELF_DRIVING" 4 "BASIC" ;
VAL_ 2047 GTW_parkAssistECUType 0 "VALEO" 1 "TESLA" ;
VAL_ 2047 GTW_softRange 0 "STANDARD" ;
VAL_ 2047 GTW_steeringColumnMotorType 0 "BOSCH" 1 "JE" ;
VAL_ 2047 GTW_brakeHWType 4 "D380_MANDO1_43_D365" 5 "D395_MANDO1_43_D365" ;
VAL_ 2047 GTW_passengerAirbagType 0 "FULL_SUPPRESSION" 1 "SAFETY_VENT" 2 "EUROW" ;
VAL_ 2047 GTW_interiorCamFanType 1 "SLEEVE" 2 "FDB" ;
VAL_ 2047 GTW_refrigerantType 0 "Default" 1 "R134A" 2 "R1234YF" ;
VAL_ 2047 GTW_superchargingAccess 0 "NOT_ALLOWED" 1 "ALLOWED" 2 "PAY_AS_YOU_GO" ;
VAL_ 2047 GTW_forwardRadarHw 0 "CONTI_ARS410" 2 "NONE" ;
VAL_ 2047 GTW_exteriorColor 0 "RED_MULTICOAT" 1 "SOLID_BLACK" 3 "MIDNIGHT_SILVER" 5 "DEEP_BLUE" 6 "PEARL_WHITE" ;
VAL_ 2047 GTW_frontSeatType 0 "BASE_TESLA" 1 "PREMIUM_TESLA" 2 "PREMIUM_L_YANFENG_R_TESLA" 3 "PREMIUM_L_TESLA_R_YANFENG" 4 "PREMIUM_YANFENG" ;
VAL_ 2047 GTW_refrigACLineType 0 "UNLIMITED" 1 "SAAA_LIMITED" 2 "CONTI_LIMITED" ;
VAL_ 2047 GTW_restraintsHardwareType 101 "MXP2" 104 "MXP2_YOKE" 171 "MSP2" 174 "MSP2_YOKE" ;
VAL_ 2047 GTW_wheelType 25 "CARDENIO_19" 26 "NEW_TURBINE_22_BLACK" 28 "CYBERSTREAM_20" 29 "ARACHNID_21" ;
VAL_ 2047 GTW_efficiencyPackage 0 "DEFAULT" ;
VAL_ 2047 GTW_tpmsType 1 "TESLA_BLE" ;
VAL_ 2047 GTW_refrigFilterType 0 "UNBLOCKED" 1 "BLOCKED_V1" ;
VAL_ 2047 GTW_diBurnInType 0 "NONE" 1 "ENABLED_V1" ;
VAL_ 2047 GTW_pedestrianWarningSound 0 "NONE" 1 "SPEAKER" 2 "EXT_SPEAKER_V2" ;
VAL_ 2047 GTW_wirelessPhoneChargerType 2 "FRONT_AND_REAR_LIN" ;
VAL_ 2047 GTW_ethernetTunerType 0 "HARMAN" 1 "NONE" ;
VAL_ 2047 GTW_steeringColumnUJointType 0 "B_SAMPLE_PHASING" 1 "C_SAMPLE_PHASING" ;
VAL_ 2047 GTW_bPillarNFCParam 0 "3" 1 "Y" ;
VAL_ 2047 GTW_drivetrainType 1 "AWD" 2 "AWD_DUAL_REAR" ;
VAL_ 2047 GTW_interiorLighting 0 "BASE" 1 "PREMIUM" ;
VAL_ 2047 GTW_towPackage 0 "NONE" 1 "TESLA_REV1" ;
VAL_ 2047 GTW_headlightLevelerType 0 "NONE" 1 "GEN1" 2 "VIRTUAL_PITCH_SENSOR" ;
VAL_ 2047 GTW_interiorTrimType 0 "BLACK" 1 "WHITE" 4 "WALNUT_CREAM" 5 "WALNUT_WHITE" 6 "EBONY_BLACK" 7 "CARBON_CREAM" 8 "CARBON_WHITE" 9 "CARBON_BLACK" ;
VAL_ 2047 GTW_radarHeaterType 0 "NONE" 3 "MODELS_BACKER_THIN_3M" 4 "MODELX_BACKER_THIN_3M" ;
VAL_ 2047 GTW_steeringHeaterType 0 "NONE" 4 "ZF_ROUND" 5 "ZF_YOKE" ;
VAL_ 2047 GTW_numberHVILNodes 0 "0" 2 "2" 3 "3" ;
VAL_ 1861 DI_counterSteerTarget 0 "INACTIVE" 1 "ACTIVE" 2 "EXPIRED" ;
VAL_ 1861 DI_turnDirection 0 "RIGHT" 1 "LEFT" ;
VAL_ 1861 DI_oppositeBuildDirFrontAxle 0 "FALSE" 1 "TRUE" ;
VAL_ 1861 DI_oppositeBuildDirRearAxle 0 "FALSE" 1 "TRUE" ;
VAL_ 1861 DI_saturatedEffectiveness 0 "FALSE" 1 "TRUE" ;
VAL_ 1861 DI_preControlOpposingTurnDir 0 "FALSE" 1 "TRUE" ;
